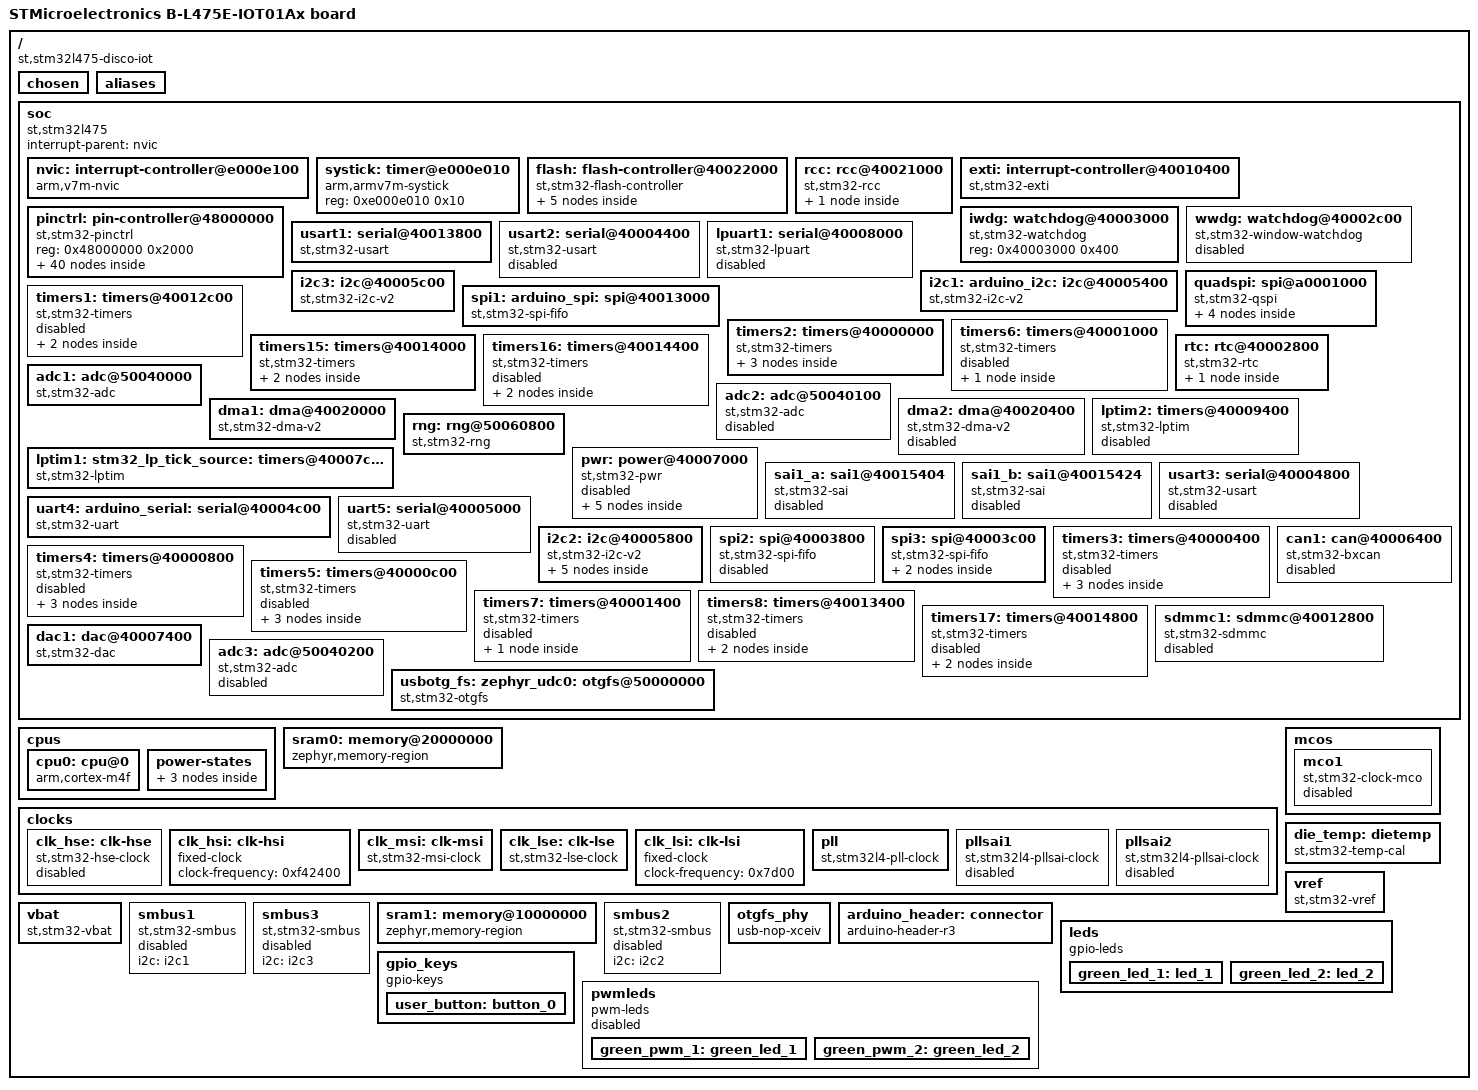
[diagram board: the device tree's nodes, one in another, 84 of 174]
/dts-v1/;

/* node '/' defined in zephyr/dts/common/skeleton.dtsi:9 */
/ {
	#address-cells = < 0x1 >;                           /* in zephyr/dts/common/skeleton.dtsi:10 */
	#size-cells = < 0x1 >;                              /* in zephyr/dts/common/skeleton.dtsi:11 */
	model = "STMicroelectronics B-L475E-IOT01Ax board"; /* in zephyr/boards/st/disco_l475_iot1/disco_l475_iot1.dts:14 */
	compatible = "st,stm32l475-disco-iot";              /* in zephyr/boards/st/disco_l475_iot1/disco_l475_iot1.dts:15 */

	/* node '/chosen' defined in zephyr/dts/common/skeleton.dtsi:13 */
	chosen {
		zephyr,entropy = &rng;                    /* in zephyr/dts/arm/st/l4/stm32l4.dtsi:26 */
		zephyr,console = &usart1;                 /* in zephyr/boards/st/disco_l475_iot1/disco_l475_iot1.dts:18 */
		zephyr,shell-uart = &usart1;              /* in zephyr/boards/st/disco_l475_iot1/disco_l475_iot1.dts:19 */
		zephyr,sram = &sram0;                     /* in zephyr/boards/st/disco_l475_iot1/disco_l475_iot1.dts:20 */
		zephyr,flash = &flash0;                   /* in zephyr/boards/st/disco_l475_iot1/disco_l475_iot1.dts:21 */
		zephyr,code-partition = &slot0_partition; /* in zephyr/boards/st/disco_l475_iot1/disco_l475_iot1.dts:22 */
		zephyr,flash-controller = &mx25r6435f;    /* in zephyr/boards/st/disco_l475_iot1/disco_l475_iot1.dts:23 */
		zephyr,bt-c2h-uart = &usart1;             /* in zephyr/boards/st/disco_l475_iot1/disco_l475_iot1.dts:24 */
		zephyr,bt-hci = &hci_spi;                 /* in zephyr/boards/st/disco_l475_iot1/disco_l475_iot1.dts:25 */
	};

	/* node '/aliases' defined in zephyr/dts/common/skeleton.dtsi:15 */
	aliases {
		led0 = &green_led_2;     /* in zephyr/boards/st/disco_l475_iot1/disco_l475_iot1.dts:73 */
		led1 = &green_led_1;     /* in zephyr/boards/st/disco_l475_iot1/disco_l475_iot1.dts:74 */
		pwm-led0 = &green_pwm_2; /* in zephyr/boards/st/disco_l475_iot1/disco_l475_iot1.dts:75 */
		pwm-led1 = &green_pwm_1; /* in zephyr/boards/st/disco_l475_iot1/disco_l475_iot1.dts:76 */
		sw0 = &user_button;      /* in zephyr/boards/st/disco_l475_iot1/disco_l475_iot1.dts:77 */
		eswifi0 = &wifi0;        /* in zephyr/boards/st/disco_l475_iot1/disco_l475_iot1.dts:78 */
		watchdog0 = &iwdg;       /* in zephyr/boards/st/disco_l475_iot1/disco_l475_iot1.dts:79 */
		accel0 = &lsm6dsl;       /* in zephyr/boards/st/disco_l475_iot1/disco_l475_iot1.dts:80 */
		volt-sensor0 = &vref;    /* in zephyr/boards/st/disco_l475_iot1/disco_l475_iot1.dts:81 */
		volt-sensor1 = &vbat;    /* in zephyr/boards/st/disco_l475_iot1/disco_l475_iot1.dts:82 */
		die-temp0 = &die_temp;   /* in zephyr/boards/st/disco_l475_iot1/disco_l475_iot1.dts:83 */
	};

	/* node '/soc' defined in zephyr/dts/arm/armv7-m.dtsi:6 */
	soc {
		#address-cells = < 0x1 >;     /* in zephyr/dts/arm/armv7-m.dtsi:7 */
		#size-cells = < 0x1 >;        /* in zephyr/dts/arm/armv7-m.dtsi:8 */
		interrupt-parent = < &nvic >; /* in zephyr/dts/arm/armv7-m.dtsi:10 */
		ranges;                       /* in zephyr/dts/arm/armv7-m.dtsi:11 */
		compatible = "st,stm32l475",
		             "st,stm32l4",
		             "simple-bus";    /* in zephyr/dts/arm/st/l4/stm32l475.dtsi:11 */

		/* node '/soc/interrupt-controller@e000e100' defined in zephyr/dts/arm/armv7-m.dtsi:13 */
		nvic: interrupt-controller@e000e100 {
			#address-cells = < 0x1 >;            /* in zephyr/dts/arm/armv7-m.dtsi:14 */
			compatible = "arm,v7m-nvic";         /* in zephyr/dts/arm/armv7-m.dtsi:15 */
			reg = < 0xe000e100 0xc00 >;          /* in zephyr/dts/arm/armv7-m.dtsi:16 */
			interrupt-controller;                /* in zephyr/dts/arm/armv7-m.dtsi:17 */
			#interrupt-cells = < 0x2 >;          /* in zephyr/dts/arm/armv7-m.dtsi:18 */
			arm,num-irq-priority-bits = < 0x4 >; /* in zephyr/dts/arm/st/l4/stm32l4.dtsi:596 */
			phandle = < 0x1 >;                   /* in zephyr/dts/arm/armv7-m.dtsi:10 */
		};

		/* node '/soc/timer@e000e010' defined in zephyr/dts/arm/armv7-m.dtsi:21 */
		systick: timer@e000e010 {
			compatible = "arm,armv7m-systick"; /* in zephyr/dts/arm/armv7-m.dtsi:22 */
			reg = < 0xe000e010 0x10 >;         /* in zephyr/dts/arm/armv7-m.dtsi:23 */
		};

		/* node '/soc/flash-controller@40022000' defined in zephyr/dts/arm/st/l4/stm32l4.dtsi:127 */
		flash: flash-controller@40022000 {
			compatible = "st,stm32-flash-controller",
			             "st,stm32l4-flash-controller"; /* in zephyr/dts/arm/st/l4/stm32l4.dtsi:128 */
			reg = < 0x40022000 0x400 >;                 /* in zephyr/dts/arm/st/l4/stm32l4.dtsi:129 */
			interrupts = < 0x4 0x0 >;                   /* in zephyr/dts/arm/st/l4/stm32l4.dtsi:130 */
			clocks = < &rcc 0x48 0x100 >;               /* in zephyr/dts/arm/st/l4/stm32l4.dtsi:131 */
			#address-cells = < 0x1 >;                   /* in zephyr/dts/arm/st/l4/stm32l4.dtsi:133 */
			#size-cells = < 0x1 >;                      /* in zephyr/dts/arm/st/l4/stm32l4.dtsi:134 */

			/* node '/soc/flash-controller@40022000/flash@8000000' defined in zephyr/dts/arm/st/l4/stm32l4.dtsi:136 */
			flash0: flash@8000000 {
				compatible = "st,stm32-nv-flash",
				             "soc-nv-flash";      /* in zephyr/dts/arm/st/l4/stm32l4.dtsi:137 */
				write-block-size = < 0x8 >;       /* in zephyr/dts/arm/st/l4/stm32l4.dtsi:139 */
				erase-block-size = < 0x800 >;     /* in zephyr/dts/arm/st/l4/stm32l4.dtsi:140 */
				max-erase-time = < 0x19 >;        /* in zephyr/dts/arm/st/l4/stm32l4.dtsi:142 */
				reg = < 0x8000000 0x100000 >;     /* in zephyr/dts/arm/st/l4/stm32l475Xg.dtsi:20 */

				/* node '/soc/flash-controller@40022000/flash@8000000/partitions' defined in zephyr/boards/st/disco_l475_iot1/disco_l475_iot1.dts:227 */
				partitions {
					compatible = "fixed-partitions"; /* in zephyr/boards/st/disco_l475_iot1/disco_l475_iot1.dts:228 */
					#address-cells = < 0x1 >;        /* in zephyr/boards/st/disco_l475_iot1/disco_l475_iot1.dts:229 */
					#size-cells = < 0x1 >;           /* in zephyr/boards/st/disco_l475_iot1/disco_l475_iot1.dts:230 */

					/* node '/soc/flash-controller@40022000/flash@8000000/partitions/partition@0' defined in zephyr/boards/st/disco_l475_iot1/disco_l475_iot1.dts:232 */
					boot_partition: partition@0 {
						label = "mcuboot";     /* in zephyr/boards/st/disco_l475_iot1/disco_l475_iot1.dts:233 */
						reg = < 0x0 0x10000 >; /* in zephyr/boards/st/disco_l475_iot1/disco_l475_iot1.dts:234 */
						read-only;             /* in zephyr/boards/st/disco_l475_iot1/disco_l475_iot1.dts:235 */
					};

					/* node '/soc/flash-controller@40022000/flash@8000000/partitions/partition@10000' defined in zephyr/boards/st/disco_l475_iot1/disco_l475_iot1.dts:238 */
					slot0_partition: partition@10000 {
						label = "image-0";         /* in zephyr/boards/st/disco_l475_iot1/disco_l475_iot1.dts:239 */
						reg = < 0x10000 0xe8000 >; /* in zephyr/boards/st/disco_l475_iot1/disco_l475_iot1.dts:240 */
					};

					/* node '/soc/flash-controller@40022000/flash@8000000/partitions/partition@f8000' defined in zephyr/boards/st/disco_l475_iot1/disco_l475_iot1.dts:243 */
					storage_partition: partition@f8000 {
						label = "storage";        /* in zephyr/boards/st/disco_l475_iot1/disco_l475_iot1.dts:244 */
						reg = < 0xf8000 0x8000 >; /* in zephyr/boards/st/disco_l475_iot1/disco_l475_iot1.dts:245 */
					};
				};
			};
		};

		/* node '/soc/rcc@40021000' defined in zephyr/dts/arm/st/l4/stm32l4.dtsi:146 */
		rcc: rcc@40021000 {
			compatible = "st,stm32-rcc";     /* in zephyr/dts/arm/st/l4/stm32l4.dtsi:147 */
			#clock-cells = < 0x2 >;          /* in zephyr/dts/arm/st/l4/stm32l4.dtsi:148 */
			reg = < 0x40021000 0x400 >;      /* in zephyr/dts/arm/st/l4/stm32l4.dtsi:149 */
			clocks = < &pll >;               /* in zephyr/boards/st/disco_l475_iot1/disco_l475_iot1.dts:116 */
			clock-frequency = < 0x4c4b400 >; /* in zephyr/boards/st/disco_l475_iot1/disco_l475_iot1.dts:117 */
			ahb-prescaler = < 0x1 >;         /* in zephyr/boards/st/disco_l475_iot1/disco_l475_iot1.dts:118 */
			apb1-prescaler = < 0x1 >;        /* in zephyr/boards/st/disco_l475_iot1/disco_l475_iot1.dts:119 */
			apb2-prescaler = < 0x1 >;        /* in zephyr/boards/st/disco_l475_iot1/disco_l475_iot1.dts:120 */
			phandle = < 0x2 >;               /* in zephyr/dts/arm/st/l4/stm32l4.dtsi:131 */

			/* node '/soc/rcc@40021000/reset-controller' defined in zephyr/dts/arm/st/l4/stm32l4.dtsi:151 */
			rctl: reset-controller {
				compatible = "st,stm32-rcc-rctl"; /* in zephyr/dts/arm/st/l4/stm32l4.dtsi:152 */
				#reset-cells = < 0x1 >;           /* in zephyr/dts/arm/st/l4/stm32l4.dtsi:153 */
				phandle = < 0x4 >;                /* in zephyr/dts/arm/st/l4/stm32l4.dtsi:230 */
			};
		};

		/* node '/soc/interrupt-controller@40010400' defined in zephyr/dts/arm/st/l4/stm32l4.dtsi:157 */
		exti: interrupt-controller@40010400 {
			compatible = "st,stm32-exti";  /* in zephyr/dts/arm/st/l4/stm32l4.dtsi:158 */
			interrupt-controller;          /* in zephyr/dts/arm/st/l4/stm32l4.dtsi:159 */
			#interrupt-cells = < 0x1 >;    /* in zephyr/dts/arm/st/l4/stm32l4.dtsi:160 */
			#address-cells = < 0x0 >;      /* in zephyr/dts/arm/st/l4/stm32l4.dtsi:161 */
			reg = < 0x40010400 0x400 >;    /* in zephyr/dts/arm/st/l4/stm32l4.dtsi:162 */
			clocks = < &rcc 0x60 0x1 >;    /* in zephyr/dts/arm/st/l4/stm32l4.dtsi:163 */
			num-lines = < 0x40 >;          /* in zephyr/dts/arm/st/l4/stm32l4.dtsi:164 */
			interrupts = < 0x6 0x0 >,
			             < 0x7 0x0 >,
			             < 0x8 0x0 >,
			             < 0x9 0x0 >,
			             < 0xa 0x0 >,
			             < 0x17 0x0 >,
			             < 0x28 0x0 >;     /* in zephyr/dts/arm/st/l4/stm32l4.dtsi:165 */
			interrupt-names = "line0",
			                  "line1",
			                  "line2",
			                  "line3",
			                  "line4",
			                  "line5-9",
			                  "line10-15"; /* in zephyr/dts/arm/st/l4/stm32l4.dtsi:167 */
			line-ranges = < 0x0 0x1 >,
			              < 0x1 0x1 >,
			              < 0x2 0x1 >,
			              < 0x3 0x1 >,
			              < 0x4 0x1 >,
			              < 0x5 0x5 >,
			              < 0xa 0x6 >;     /* in zephyr/dts/arm/st/l4/stm32l4.dtsi:169 */
		};

		/* node '/soc/pin-controller@48000000' defined in zephyr/dts/arm/st/l4/stm32l4.dtsi:173 */
		pinctrl: pin-controller@48000000 {
			compatible = "st,stm32-pinctrl"; /* in zephyr/dts/arm/st/l4/stm32l4.dtsi:174 */
			#address-cells = < 0x1 >;        /* in zephyr/dts/arm/st/l4/stm32l4.dtsi:175 */
			#size-cells = < 0x1 >;           /* in zephyr/dts/arm/st/l4/stm32l4.dtsi:176 */
			reg = < 0x48000000 0x2000 >;     /* in zephyr/dts/arm/st/l4/stm32l4.dtsi:177 */

			/* node '/soc/pin-controller@48000000/gpio@48000000' defined in zephyr/dts/arm/st/l4/stm32l4.dtsi:179 */
			gpioa: gpio@48000000 {
				compatible = "st,stm32-gpio"; /* in zephyr/dts/arm/st/l4/stm32l4.dtsi:180 */
				gpio-controller;              /* in zephyr/dts/arm/st/l4/stm32l4.dtsi:181 */
				#gpio-cells = < 0x2 >;        /* in zephyr/dts/arm/st/l4/stm32l4.dtsi:182 */
				reg = < 0x48000000 0x400 >;   /* in zephyr/dts/arm/st/l4/stm32l4.dtsi:183 */
				clocks = < &rcc 0x4c 0x1 >;   /* in zephyr/dts/arm/st/l4/stm32l4.dtsi:184 */
				phandle = < 0x15 >;           /* in zephyr/boards/st/disco_l475_iot1/disco_l475_iot1.dts:189 */
			};

			/* node '/soc/pin-controller@48000000/gpio@48000400' defined in zephyr/dts/arm/st/l4/stm32l4.dtsi:187 */
			gpiob: gpio@48000400 {
				compatible = "st,stm32-gpio"; /* in zephyr/dts/arm/st/l4/stm32l4.dtsi:188 */
				gpio-controller;              /* in zephyr/dts/arm/st/l4/stm32l4.dtsi:189 */
				#gpio-cells = < 0x2 >;        /* in zephyr/dts/arm/st/l4/stm32l4.dtsi:190 */
				reg = < 0x48000400 0x400 >;   /* in zephyr/dts/arm/st/l4/stm32l4.dtsi:191 */
				clocks = < &rcc 0x4c 0x2 >;   /* in zephyr/dts/arm/st/l4/stm32l4.dtsi:192 */
				phandle = < 0x27 >;           /* in zephyr/boards/st/disco_l475_iot1/disco_l475_iot1.dts:220 */
			};

			/* node '/soc/pin-controller@48000000/gpio@48000800' defined in zephyr/dts/arm/st/l4/stm32l4.dtsi:195 */
			gpioc: gpio@48000800 {
				compatible = "st,stm32-gpio"; /* in zephyr/dts/arm/st/l4/stm32l4.dtsi:196 */
				gpio-controller;              /* in zephyr/dts/arm/st/l4/stm32l4.dtsi:197 */
				#gpio-cells = < 0x2 >;        /* in zephyr/dts/arm/st/l4/stm32l4.dtsi:198 */
				reg = < 0x48000800 0x400 >;   /* in zephyr/dts/arm/st/l4/stm32l4.dtsi:199 */
				clocks = < &rcc 0x4c 0x4 >;   /* in zephyr/dts/arm/st/l4/stm32l4.dtsi:200 */
				phandle = < 0x22 >;           /* in zephyr/boards/st/disco_l475_iot1/disco_l475_iot1.dts:175 */
			};

			/* node '/soc/pin-controller@48000000/gpio@48001c00' defined in zephyr/dts/arm/st/l4/stm32l4.dtsi:203 */
			gpioh: gpio@48001c00 {
				compatible = "st,stm32-gpio"; /* in zephyr/dts/arm/st/l4/stm32l4.dtsi:204 */
				gpio-controller;              /* in zephyr/dts/arm/st/l4/stm32l4.dtsi:205 */
				#gpio-cells = < 0x2 >;        /* in zephyr/dts/arm/st/l4/stm32l4.dtsi:206 */
				reg = < 0x48001c00 0x400 >;   /* in zephyr/dts/arm/st/l4/stm32l4.dtsi:207 */
				clocks = < &rcc 0x4c 0x80 >;  /* in zephyr/dts/arm/st/l4/stm32l4.dtsi:208 */
			};

			/* node '/soc/pin-controller@48000000/gpio@48000c00' defined in zephyr/dts/arm/st/l4/stm32l471.dtsi:29 */
			gpiod: gpio@48000c00 {
				compatible = "st,stm32-gpio"; /* in zephyr/dts/arm/st/l4/stm32l471.dtsi:30 */
				gpio-controller;              /* in zephyr/dts/arm/st/l4/stm32l471.dtsi:31 */
				#gpio-cells = < 0x2 >;        /* in zephyr/dts/arm/st/l4/stm32l471.dtsi:32 */
				reg = < 0x48000c00 0x400 >;   /* in zephyr/dts/arm/st/l4/stm32l471.dtsi:33 */
				clocks = < &rcc 0x4c 0x8 >;   /* in zephyr/dts/arm/st/l4/stm32l471.dtsi:34 */
				phandle = < 0x21 >;           /* in zephyr/boards/st/disco_l475_iot1/disco_l475_iot1.dts:158 */
			};

			/* node '/soc/pin-controller@48000000/gpio@48001000' defined in zephyr/dts/arm/st/l4/stm32l471.dtsi:37 */
			gpioe: gpio@48001000 {
				compatible = "st,stm32-gpio"; /* in zephyr/dts/arm/st/l4/stm32l471.dtsi:38 */
				gpio-controller;              /* in zephyr/dts/arm/st/l4/stm32l471.dtsi:39 */
				#gpio-cells = < 0x2 >;        /* in zephyr/dts/arm/st/l4/stm32l471.dtsi:40 */
				reg = < 0x48001000 0x400 >;   /* in zephyr/dts/arm/st/l4/stm32l471.dtsi:41 */
				clocks = < &rcc 0x4c 0x10 >;  /* in zephyr/dts/arm/st/l4/stm32l471.dtsi:42 */
				phandle = < 0x26 >;           /* in zephyr/boards/st/disco_l475_iot1/disco_l475_iot1.dts:203 */
			};

			/* node '/soc/pin-controller@48000000/gpio@48001400' defined in zephyr/dts/arm/st/l4/stm32l471.dtsi:45 */
			gpiof: gpio@48001400 {
				compatible = "st,stm32-gpio"; /* in zephyr/dts/arm/st/l4/stm32l471.dtsi:46 */
				gpio-controller;              /* in zephyr/dts/arm/st/l4/stm32l471.dtsi:47 */
				#gpio-cells = < 0x2 >;        /* in zephyr/dts/arm/st/l4/stm32l471.dtsi:48 */
				reg = < 0x48001400 0x400 >;   /* in zephyr/dts/arm/st/l4/stm32l471.dtsi:49 */
				clocks = < &rcc 0x4c 0x20 >;  /* in zephyr/dts/arm/st/l4/stm32l471.dtsi:50 */
			};

			/* node '/soc/pin-controller@48000000/gpio@48001800' defined in zephyr/dts/arm/st/l4/stm32l471.dtsi:53 */
			gpiog: gpio@48001800 {
				compatible = "st,stm32-gpio"; /* in zephyr/dts/arm/st/l4/stm32l471.dtsi:54 */
				gpio-controller;              /* in zephyr/dts/arm/st/l4/stm32l471.dtsi:55 */
				#gpio-cells = < 0x2 >;        /* in zephyr/dts/arm/st/l4/stm32l471.dtsi:56 */
				reg = < 0x48001800 0x400 >;   /* in zephyr/dts/arm/st/l4/stm32l471.dtsi:57 */
				clocks = < &rcc 0x4c 0x40 >;  /* in zephyr/dts/arm/st/l4/stm32l471.dtsi:58 */
			};

			/* node '/soc/pin-controller@48000000/adc1_in3_pc2' defined in modules/hal/stm32/dts/st/l4/stm32l475v(c-e-g)tx-pinctrl.dtsi:63 */
			adc1_in3_pc2: adc1_in3_pc2 {
				pinmux = < 0x450 >; /* in modules/hal/stm32/dts/st/l4/stm32l475v(c-e-g)tx-pinctrl.dtsi:64 */
				phandle = < 0x18 >; /* in zephyr/boards/st/disco_l475_iot1/disco_l475_iot1.dts:300 */
			};

			/* node '/soc/pin-controller@48000000/adc1_in4_pc3' defined in modules/hal/stm32/dts/st/l4/stm32l475v(c-e-g)tx-pinctrl.dtsi:67 */
			adc1_in4_pc3: adc1_in4_pc3 {
				pinmux = < 0x470 >; /* in modules/hal/stm32/dts/st/l4/stm32l475v(c-e-g)tx-pinctrl.dtsi:68 */
				phandle = < 0x19 >; /* in zephyr/boards/st/disco_l475_iot1/disco_l475_iot1.dts:300 */
			};

			/* node '/soc/pin-controller@48000000/adc1_in13_pc4' defined in modules/hal/stm32/dts/st/l4/stm32l475v(c-e-g)tx-pinctrl.dtsi:71 */
			adc1_in13_pc4: adc1_in13_pc4 {
				pinmux = < 0x490 >; /* in modules/hal/stm32/dts/st/l4/stm32l475v(c-e-g)tx-pinctrl.dtsi:72 */
				phandle = < 0x1a >; /* in zephyr/boards/st/disco_l475_iot1/disco_l475_iot1.dts:300 */
			};

			/* node '/soc/pin-controller@48000000/adc1_in14_pc5' defined in modules/hal/stm32/dts/st/l4/stm32l475v(c-e-g)tx-pinctrl.dtsi:75 */
			adc1_in14_pc5: adc1_in14_pc5 {
				pinmux = < 0x4b0 >; /* in modules/hal/stm32/dts/st/l4/stm32l475v(c-e-g)tx-pinctrl.dtsi:76 */
				phandle = < 0x1b >; /* in zephyr/boards/st/disco_l475_iot1/disco_l475_iot1.dts:300 */
			};

			/* node '/soc/pin-controller@48000000/dac1_out1_pa4' defined in modules/hal/stm32/dts/st/l4/stm32l475v(c-e-g)tx-pinctrl.dtsi:574 */
			dac1_out1_pa4: dac1_out1_pa4 {
				pinmux = < 0x90 >;  /* in modules/hal/stm32/dts/st/l4/stm32l475v(c-e-g)tx-pinctrl.dtsi:575 */
				phandle = < 0x28 >; /* in zephyr/boards/st/disco_l475_iot1/disco_l475_iot1.dts:314 */
			};

			/* node '/soc/pin-controller@48000000/i2c1_scl_pb8' defined in modules/hal/stm32/dts/st/l4/stm32l475v(c-e-g)tx-pinctrl.dtsi:958 */
			i2c1_scl_pb8: i2c1_scl_pb8 {
				pinmux = < 0x304 >; /* in modules/hal/stm32/dts/st/l4/stm32l475v(c-e-g)tx-pinctrl.dtsi:959 */
				bias-pull-up;       /* in modules/hal/stm32/dts/st/l4/stm32l475v(c-e-g)tx-pinctrl.dtsi:960 */
				drive-open-drain;   /* in modules/hal/stm32/dts/st/l4/stm32l475v(c-e-g)tx-pinctrl.dtsi:961 */
				phandle = < 0x7 >;  /* in zephyr/boards/st/disco_l475_iot1/disco_l475_iot1.dts:138 */
			};

			/* node '/soc/pin-controller@48000000/i2c2_scl_pb10' defined in modules/hal/stm32/dts/st/l4/stm32l475v(c-e-g)tx-pinctrl.dtsi:964 */
			i2c2_scl_pb10: i2c2_scl_pb10 {
				pinmux = < 0x344 >; /* in modules/hal/stm32/dts/st/l4/stm32l475v(c-e-g)tx-pinctrl.dtsi:965 */
				bias-pull-up;       /* in modules/hal/stm32/dts/st/l4/stm32l475v(c-e-g)tx-pinctrl.dtsi:966 */
				drive-open-drain;   /* in modules/hal/stm32/dts/st/l4/stm32l475v(c-e-g)tx-pinctrl.dtsi:967 */
				phandle = < 0x1f >; /* in zephyr/boards/st/disco_l475_iot1/disco_l475_iot1.dts:145 */
			};

			/* node '/soc/pin-controller@48000000/i2c3_scl_pc0' defined in modules/hal/stm32/dts/st/l4/stm32l475v(c-e-g)tx-pinctrl.dtsi:976 */
			i2c3_scl_pc0: i2c3_scl_pc0 {
				pinmux = < 0x404 >; /* in modules/hal/stm32/dts/st/l4/stm32l475v(c-e-g)tx-pinctrl.dtsi:977 */
				bias-pull-up;       /* in modules/hal/stm32/dts/st/l4/stm32l475v(c-e-g)tx-pinctrl.dtsi:978 */
				drive-open-drain;   /* in modules/hal/stm32/dts/st/l4/stm32l475v(c-e-g)tx-pinctrl.dtsi:979 */
				phandle = < 0x9 >;  /* in zephyr/boards/st/disco_l475_iot1/disco_l475_iot1.dts:180 */
			};

			/* node '/soc/pin-controller@48000000/i2c1_sda_pb9' defined in modules/hal/stm32/dts/st/l4/stm32l475v(c-e-g)tx-pinctrl.dtsi:990 */
			i2c1_sda_pb9: i2c1_sda_pb9 {
				pinmux = < 0x324 >; /* in modules/hal/stm32/dts/st/l4/stm32l475v(c-e-g)tx-pinctrl.dtsi:991 */
				bias-pull-up;       /* in modules/hal/stm32/dts/st/l4/stm32l475v(c-e-g)tx-pinctrl.dtsi:992 */
				drive-open-drain;   /* in modules/hal/stm32/dts/st/l4/stm32l475v(c-e-g)tx-pinctrl.dtsi:993 */
				phandle = < 0x8 >;  /* in zephyr/boards/st/disco_l475_iot1/disco_l475_iot1.dts:138 */
			};

			/* node '/soc/pin-controller@48000000/i2c2_sda_pb11' defined in modules/hal/stm32/dts/st/l4/stm32l475v(c-e-g)tx-pinctrl.dtsi:996 */
			i2c2_sda_pb11: i2c2_sda_pb11 {
				pinmux = < 0x364 >; /* in modules/hal/stm32/dts/st/l4/stm32l475v(c-e-g)tx-pinctrl.dtsi:997 */
				bias-pull-up;       /* in modules/hal/stm32/dts/st/l4/stm32l475v(c-e-g)tx-pinctrl.dtsi:998 */
				drive-open-drain;   /* in modules/hal/stm32/dts/st/l4/stm32l475v(c-e-g)tx-pinctrl.dtsi:999 */
				phandle = < 0x20 >; /* in zephyr/boards/st/disco_l475_iot1/disco_l475_iot1.dts:145 */
			};

			/* node '/soc/pin-controller@48000000/i2c3_sda_pc1' defined in modules/hal/stm32/dts/st/l4/stm32l475v(c-e-g)tx-pinctrl.dtsi:1008 */
			i2c3_sda_pc1: i2c3_sda_pc1 {
				pinmux = < 0x424 >; /* in modules/hal/stm32/dts/st/l4/stm32l475v(c-e-g)tx-pinctrl.dtsi:1009 */
				bias-pull-up;       /* in modules/hal/stm32/dts/st/l4/stm32l475v(c-e-g)tx-pinctrl.dtsi:1010 */
				drive-open-drain;   /* in modules/hal/stm32/dts/st/l4/stm32l475v(c-e-g)tx-pinctrl.dtsi:1011 */
				phandle = < 0xa >;  /* in zephyr/boards/st/disco_l475_iot1/disco_l475_iot1.dts:180 */
			};

			/* node '/soc/pin-controller@48000000/quadspi_clk_pe10' defined in modules/hal/stm32/dts/st/l4/stm32l475v(c-e-g)tx-pinctrl.dtsi:1111 */
			quadspi_clk_pe10: quadspi_clk_pe10 {
				pinmux = < 0x94a >;            /* in modules/hal/stm32/dts/st/l4/stm32l475v(c-e-g)tx-pinctrl.dtsi:1112 */
				slew-rate = "very-high-speed"; /* in modules/hal/stm32/dts/st/l4/stm32l475v(c-e-g)tx-pinctrl.dtsi:1113 */
				phandle = < 0xb >;             /* in zephyr/boards/st/disco_l475_iot1/disco_l475_iot1.dts:323 */
			};

			/* node '/soc/pin-controller@48000000/quadspi_ncs_pe11' defined in modules/hal/stm32/dts/st/l4/stm32l475v(c-e-g)tx-pinctrl.dtsi:1116 */
			quadspi_ncs_pe11: quadspi_ncs_pe11 {
				pinmux = < 0x96a >;            /* in modules/hal/stm32/dts/st/l4/stm32l475v(c-e-g)tx-pinctrl.dtsi:1117 */
				slew-rate = "very-high-speed"; /* in modules/hal/stm32/dts/st/l4/stm32l475v(c-e-g)tx-pinctrl.dtsi:1118 */
				phandle = < 0xc >;             /* in zephyr/boards/st/disco_l475_iot1/disco_l475_iot1.dts:323 */
			};

			/* node '/soc/pin-controller@48000000/quadspi_bk1_io0_pe12' defined in modules/hal/stm32/dts/st/l4/stm32l475v(c-e-g)tx-pinctrl.dtsi:1121 */
			quadspi_bk1_io0_pe12: quadspi_bk1_io0_pe12 {
				pinmux = < 0x98a >;            /* in modules/hal/stm32/dts/st/l4/stm32l475v(c-e-g)tx-pinctrl.dtsi:1122 */
				slew-rate = "very-high-speed"; /* in modules/hal/stm32/dts/st/l4/stm32l475v(c-e-g)tx-pinctrl.dtsi:1123 */
				phandle = < 0xd >;             /* in zephyr/boards/st/disco_l475_iot1/disco_l475_iot1.dts:323 */
			};

			/* node '/soc/pin-controller@48000000/quadspi_bk1_io1_pe13' defined in modules/hal/stm32/dts/st/l4/stm32l475v(c-e-g)tx-pinctrl.dtsi:1126 */
			quadspi_bk1_io1_pe13: quadspi_bk1_io1_pe13 {
				pinmux = < 0x9aa >;            /* in modules/hal/stm32/dts/st/l4/stm32l475v(c-e-g)tx-pinctrl.dtsi:1127 */
				slew-rate = "very-high-speed"; /* in modules/hal/stm32/dts/st/l4/stm32l475v(c-e-g)tx-pinctrl.dtsi:1128 */
				phandle = < 0xe >;             /* in zephyr/boards/st/disco_l475_iot1/disco_l475_iot1.dts:323 */
			};

			/* node '/soc/pin-controller@48000000/quadspi_bk1_io2_pe14' defined in modules/hal/stm32/dts/st/l4/stm32l475v(c-e-g)tx-pinctrl.dtsi:1131 */
			quadspi_bk1_io2_pe14: quadspi_bk1_io2_pe14 {
				pinmux = < 0x9ca >;            /* in modules/hal/stm32/dts/st/l4/stm32l475v(c-e-g)tx-pinctrl.dtsi:1132 */
				slew-rate = "very-high-speed"; /* in modules/hal/stm32/dts/st/l4/stm32l475v(c-e-g)tx-pinctrl.dtsi:1133 */
				phandle = < 0xf >;             /* in zephyr/boards/st/disco_l475_iot1/disco_l475_iot1.dts:323 */
			};

			/* node '/soc/pin-controller@48000000/quadspi_bk1_io3_pe15' defined in modules/hal/stm32/dts/st/l4/stm32l475v(c-e-g)tx-pinctrl.dtsi:1136 */
			quadspi_bk1_io3_pe15: quadspi_bk1_io3_pe15 {
				pinmux = < 0x9ea >;            /* in modules/hal/stm32/dts/st/l4/stm32l475v(c-e-g)tx-pinctrl.dtsi:1137 */
				slew-rate = "very-high-speed"; /* in modules/hal/stm32/dts/st/l4/stm32l475v(c-e-g)tx-pinctrl.dtsi:1138 */
				phandle = < 0x10 >;            /* in zephyr/boards/st/disco_l475_iot1/disco_l475_iot1.dts:323 */
			};

			/* node '/soc/pin-controller@48000000/spi1_miso_pa6' defined in modules/hal/stm32/dts/st/l4/stm32l475v(c-e-g)tx-pinctrl.dtsi:1358 */
			spi1_miso_pa6: spi1_miso_pa6 {
				pinmux = < 0xc5 >;  /* in modules/hal/stm32/dts/st/l4/stm32l475v(c-e-g)tx-pinctrl.dtsi:1359 */
				bias-pull-down;     /* in modules/hal/stm32/dts/st/l4/stm32l475v(c-e-g)tx-pinctrl.dtsi:1360 */
				phandle = < 0x13 >; /* in zephyr/boards/st/disco_l475_iot1/disco_l475_iot1.dts:187 */
			};

			/* node '/soc/pin-controller@48000000/spi3_miso_pc11' defined in modules/hal/stm32/dts/st/l4/stm32l475v(c-e-g)tx-pinctrl.dtsi:1393 */
			spi3_miso_pc11: spi3_miso_pc11 {
				pinmux = < 0x566 >;            /* in modules/hal/stm32/dts/st/l4/stm32l475v(c-e-g)tx-pinctrl.dtsi:1394 */
				bias-pull-down;                /* in modules/hal/stm32/dts/st/l4/stm32l475v(c-e-g)tx-pinctrl.dtsi:1395 */
				slew-rate = "very-high-speed"; /* in zephyr/boards/st/disco_l475_iot1/disco_l475_iot1.dts:194 */
				phandle = < 0x24 >;            /* in zephyr/boards/st/disco_l475_iot1/disco_l475_iot1.dts:200 */
			};

			/* node '/soc/pin-controller@48000000/spi1_mosi_pa7' defined in modules/hal/stm32/dts/st/l4/stm32l475v(c-e-g)tx-pinctrl.dtsi:1400 */
			spi1_mosi_pa7: spi1_mosi_pa7 {
				pinmux = < 0xe5 >;  /* in modules/hal/stm32/dts/st/l4/stm32l475v(c-e-g)tx-pinctrl.dtsi:1401 */
				bias-pull-down;     /* in modules/hal/stm32/dts/st/l4/stm32l475v(c-e-g)tx-pinctrl.dtsi:1402 */
				phandle = < 0x14 >; /* in zephyr/boards/st/disco_l475_iot1/disco_l475_iot1.dts:187 */
			};

			/* node '/soc/pin-controller@48000000/spi3_mosi_pc12' defined in modules/hal/stm32/dts/st/l4/stm32l475v(c-e-g)tx-pinctrl.dtsi:1435 */
			spi3_mosi_pc12: spi3_mosi_pc12 {
				pinmux = < 0x586 >; /* in modules/hal/stm32/dts/st/l4/stm32l475v(c-e-g)tx-pinctrl.dtsi:1436 */
				bias-pull-down;     /* in modules/hal/stm32/dts/st/l4/stm32l475v(c-e-g)tx-pinctrl.dtsi:1437 */
				phandle = < 0x25 >; /* in zephyr/boards/st/disco_l475_iot1/disco_l475_iot1.dts:200 */
			};

			/* node '/soc/pin-controller@48000000/spi1_sck_pa5' defined in modules/hal/stm32/dts/st/l4/stm32l475v(c-e-g)tx-pinctrl.dtsi:1484 */
			spi1_sck_pa5: spi1_sck_pa5 {
				pinmux = < 0xa5 >;             /* in modules/hal/stm32/dts/st/l4/stm32l475v(c-e-g)tx-pinctrl.dtsi:1485 */
				bias-pull-down;                /* in modules/hal/stm32/dts/st/l4/stm32l475v(c-e-g)tx-pinctrl.dtsi:1486 */
				slew-rate = "very-high-speed"; /* in modules/hal/stm32/dts/st/l4/stm32l475v(c-e-g)tx-pinctrl.dtsi:1487 */
				phandle = < 0x12 >;            /* in zephyr/boards/st/disco_l475_iot1/disco_l475_iot1.dts:187 */
			};

			/* node '/soc/pin-controller@48000000/spi3_sck_pc10' defined in modules/hal/stm32/dts/st/l4/stm32l475v(c-e-g)tx-pinctrl.dtsi:1526 */
			spi3_sck_pc10: spi3_sck_pc10 {
				pinmux = < 0x546 >;            /* in modules/hal/stm32/dts/st/l4/stm32l475v(c-e-g)tx-pinctrl.dtsi:1527 */
				bias-pull-down;                /* in modules/hal/stm32/dts/st/l4/stm32l475v(c-e-g)tx-pinctrl.dtsi:1528 */
				slew-rate = "very-high-speed"; /* in modules/hal/stm32/dts/st/l4/stm32l475v(c-e-g)tx-pinctrl.dtsi:1529 */
				phandle = < 0x23 >;            /* in zephyr/boards/st/disco_l475_iot1/disco_l475_iot1.dts:200 */
			};

			/* node '/soc/pin-controller@48000000/tim2_ch1_pa15' defined in modules/hal/stm32/dts/st/l4/stm32l475v(c-e-g)tx-pinctrl.dtsi:1680 */
			tim2_ch1_pa15: tim2_ch1_pa15 {
				pinmux = < 0x1e1 >; /* in modules/hal/stm32/dts/st/l4/stm32l475v(c-e-g)tx-pinctrl.dtsi:1681 */
				phandle = < 0x16 >; /* in zephyr/boards/st/disco_l475_iot1/disco_l475_iot1.dts:256 */
			};

			/* node '/soc/pin-controller@48000000/tim15_ch1_pb14' defined in modules/hal/stm32/dts/st/l4/stm32l475v(c-e-g)tx-pinctrl.dtsi:1816 */
			tim15_ch1_pb14: tim15_ch1_pb14 {
				pinmux = < 0x3ce >; /* in modules/hal/stm32/dts/st/l4/stm32l475v(c-e-g)tx-pinctrl.dtsi:1817 */
				phandle = < 0x17 >; /* in zephyr/boards/st/disco_l475_iot1/disco_l475_iot1.dts:267 */
			};

			/* node '/soc/pin-controller@48000000/usart1_rx_pb7' defined in modules/hal/stm32/dts/st/l4/stm32l475v(c-e-g)tx-pinctrl.dtsi:2186 */
			usart1_rx_pb7: usart1_rx_pb7 {
				pinmux = < 0x2e7 >; /* in modules/hal/stm32/dts/st/l4/stm32l475v(c-e-g)tx-pinctrl.dtsi:2187 */
				phandle = < 0x6 >;  /* in zephyr/boards/st/disco_l475_iot1/disco_l475_iot1.dts:125 */
			};

			/* node '/soc/pin-controller@48000000/uart4_rx_pa1' defined in modules/hal/stm32/dts/st/l4/stm32l475v(c-e-g)tx-pinctrl.dtsi:2222 */
			uart4_rx_pa1: uart4_rx_pa1 {
				pinmux = < 0x28 >;  /* in modules/hal/stm32/dts/st/l4/stm32l475v(c-e-g)tx-pinctrl.dtsi:2223 */
				phandle = < 0x1e >; /* in zephyr/boards/st/disco_l475_iot1/disco_l475_iot1.dts:131 */
			};

			/* node '/soc/pin-controller@48000000/usart1_tx_pb6' defined in modules/hal/stm32/dts/st/l4/stm32l475v(c-e-g)tx-pinctrl.dtsi:2241 */
			usart1_tx_pb6: usart1_tx_pb6 {
				pinmux = < 0x2c7 >; /* in modules/hal/stm32/dts/st/l4/stm32l475v(c-e-g)tx-pinctrl.dtsi:2242 */
				bias-pull-up;       /* in modules/hal/stm32/dts/st/l4/stm32l475v(c-e-g)tx-pinctrl.dtsi:2243 */
				phandle = < 0x5 >;  /* in zephyr/boards/st/disco_l475_iot1/disco_l475_iot1.dts:125 */
			};

			/* node '/soc/pin-controller@48000000/uart4_tx_pa0' defined in modules/hal/stm32/dts/st/l4/stm32l475v(c-e-g)tx-pinctrl.dtsi:2286 */
			uart4_tx_pa0: uart4_tx_pa0 {
				pinmux = < 0x8 >;   /* in modules/hal/stm32/dts/st/l4/stm32l475v(c-e-g)tx-pinctrl.dtsi:2287 */
				bias-pull-up;       /* in modules/hal/stm32/dts/st/l4/stm32l475v(c-e-g)tx-pinctrl.dtsi:2288 */
				phandle = < 0x1d >; /* in zephyr/boards/st/disco_l475_iot1/disco_l475_iot1.dts:131 */
			};

			/* node '/soc/pin-controller@48000000/usb_otg_fs_id_pa10' defined in modules/hal/stm32/dts/st/l4/stm32l475v(c-e-g)tx-pinctrl.dtsi:2311 */
			usb_otg_fs_id_pa10: usb_otg_fs_id_pa10 {
				pinmux = < 0x14a >; /* in modules/hal/stm32/dts/st/l4/stm32l475v(c-e-g)tx-pinctrl.dtsi:2312 */
				phandle = < 0x2c >; /* in zephyr/boards/st/disco_l475_iot1/disco_l475_iot1.dts:285 */
			};

			/* node '/soc/pin-controller@48000000/usb_otg_fs_dm_pa11' defined in modules/hal/stm32/dts/st/l4/stm32l475v(c-e-g)tx-pinctrl.dtsi:2315 */
			usb_otg_fs_dm_pa11: usb_otg_fs_dm_pa11 {
				pinmux = < 0x16a >; /* in modules/hal/stm32/dts/st/l4/stm32l475v(c-e-g)tx-pinctrl.dtsi:2316 */
				phandle = < 0x2a >; /* in zephyr/boards/st/disco_l475_iot1/disco_l475_iot1.dts:285 */
			};

			/* node '/soc/pin-controller@48000000/usb_otg_fs_dp_pa12' defined in modules/hal/stm32/dts/st/l4/stm32l475v(c-e-g)tx-pinctrl.dtsi:2319 */
			usb_otg_fs_dp_pa12: usb_otg_fs_dp_pa12 {
				pinmux = < 0x18a >; /* in modules/hal/stm32/dts/st/l4/stm32l475v(c-e-g)tx-pinctrl.dtsi:2320 */
				phandle = < 0x2b >; /* in zephyr/boards/st/disco_l475_iot1/disco_l475_iot1.dts:285 */
			};
		};

		/* node '/soc/watchdog@40003000' defined in zephyr/dts/arm/st/l4/stm32l4.dtsi:212 */
		iwdg: watchdog@40003000 {
			compatible = "st,stm32-watchdog"; /* in zephyr/dts/arm/st/l4/stm32l4.dtsi:213 */
			reg = < 0x40003000 0x400 >;       /* in zephyr/dts/arm/st/l4/stm32l4.dtsi:214 */
			status = "okay";                  /* in zephyr/boards/st/disco_l475_iot1/disco_l475_iot1.dts:292 */
		};

		/* node '/soc/watchdog@40002c00' defined in zephyr/dts/arm/st/l4/stm32l4.dtsi:218 */
		wwdg: watchdog@40002c00 {
			compatible = "st,stm32-window-watchdog"; /* in zephyr/dts/arm/st/l4/stm32l4.dtsi:219 */
			reg = < 0x40002c00 0x400 >;              /* in zephyr/dts/arm/st/l4/stm32l4.dtsi:220 */
			clocks = < &rcc 0x58 0x800 >;            /* in zephyr/dts/arm/st/l4/stm32l4.dtsi:221 */
			interrupts = < 0x0 0x7 >;                /* in zephyr/dts/arm/st/l4/stm32l4.dtsi:222 */
			status = "disabled";                     /* in zephyr/dts/arm/st/l4/stm32l4.dtsi:223 */
		};

		/* node '/soc/serial@40013800' defined in zephyr/dts/arm/st/l4/stm32l4.dtsi:226 */
		usart1: serial@40013800 {
			compatible = "st,stm32-usart",
			             "st,stm32-uart";                  /* in zephyr/dts/arm/st/l4/stm32l4.dtsi:227 */
			reg = < 0x40013800 0x400 >;                    /* in zephyr/dts/arm/st/l4/stm32l4.dtsi:228 */
			clocks = < &rcc 0x60 0x4000 >;                 /* in zephyr/dts/arm/st/l4/stm32l4.dtsi:229 */
			resets = < &rctl 0x80e >;                      /* in zephyr/dts/arm/st/l4/stm32l4.dtsi:230 */
			interrupts = < 0x25 0x0 >;                     /* in zephyr/dts/arm/st/l4/stm32l4.dtsi:231 */
			current-speed = < 0x1c200 >;                   /* in zephyr/boards/st/disco_l475_iot1/disco_l475_iot1.dts:124 */
			pinctrl-0 = < &usart1_tx_pb6 &usart1_rx_pb7 >; /* in zephyr/boards/st/disco_l475_iot1/disco_l475_iot1.dts:125 */
			pinctrl-names = "default";                     /* in zephyr/boards/st/disco_l475_iot1/disco_l475_iot1.dts:126 */
			status = "okay";                               /* in zephyr/boards/st/disco_l475_iot1/disco_l475_iot1.dts:127 */
		};

		/* node '/soc/serial@40004400' defined in zephyr/dts/arm/st/l4/stm32l4.dtsi:235 */
		usart2: serial@40004400 {
			compatible = "st,stm32-usart",
			             "st,stm32-uart";   /* in zephyr/dts/arm/st/l4/stm32l4.dtsi:236 */
			reg = < 0x40004400 0x400 >;     /* in zephyr/dts/arm/st/l4/stm32l4.dtsi:237 */
			clocks = < &rcc 0x58 0x20000 >; /* in zephyr/dts/arm/st/l4/stm32l4.dtsi:238 */
			resets = < &rctl 0x711 >;       /* in zephyr/dts/arm/st/l4/stm32l4.dtsi:239 */
			interrupts = < 0x26 0x0 >;      /* in zephyr/dts/arm/st/l4/stm32l4.dtsi:240 */
			status = "disabled";            /* in zephyr/dts/arm/st/l4/stm32l4.dtsi:241 */
		};

		/* node '/soc/serial@40008000' defined in zephyr/dts/arm/st/l4/stm32l4.dtsi:244 */
		lpuart1: serial@40008000 {
			compatible = "st,stm32-lpuart",
			             "st,stm32-uart";   /* in zephyr/dts/arm/st/l4/stm32l4.dtsi:245 */
			reg = < 0x40008000 0x400 >;     /* in zephyr/dts/arm/st/l4/stm32l4.dtsi:246 */
			clocks = < &rcc 0x5c 0x1 >;     /* in zephyr/dts/arm/st/l4/stm32l4.dtsi:247 */
			resets = < &rctl 0x780 >;       /* in zephyr/dts/arm/st/l4/stm32l4.dtsi:248 */
			interrupts = < 0x46 0x0 >;      /* in zephyr/dts/arm/st/l4/stm32l4.dtsi:249 */
			status = "disabled";            /* in zephyr/dts/arm/st/l4/stm32l4.dtsi:250 */
		};

		/* node '/soc/i2c@40005400' defined in zephyr/dts/arm/st/l4/stm32l4.dtsi:253 */
		i2c1: arduino_i2c: i2c@40005400 {
			compatible = "st,stm32-i2c-v2";              /* in zephyr/dts/arm/st/l4/stm32l4.dtsi:254 */
			#address-cells = < 0x1 >;                    /* in zephyr/dts/arm/st/l4/stm32l4.dtsi:256 */
			#size-cells = < 0x0 >;                       /* in zephyr/dts/arm/st/l4/stm32l4.dtsi:257 */
			reg = < 0x40005400 0x400 >;                  /* in zephyr/dts/arm/st/l4/stm32l4.dtsi:258 */
			clocks = < &rcc 0x58 0x200000 >;             /* in zephyr/dts/arm/st/l4/stm32l4.dtsi:259 */
			interrupts = < 0x1f 0x0 >,
			             < 0x20 0x0 >;                   /* in zephyr/dts/arm/st/l4/stm32l4.dtsi:260 */
			interrupt-names = "event",
			                  "error";                   /* in zephyr/dts/arm/st/l4/stm32l4.dtsi:261 */
			pinctrl-0 = < &i2c1_scl_pb8 &i2c1_sda_pb9 >; /* in zephyr/boards/st/disco_l475_iot1/disco_l475_iot1.dts:138 */
			pinctrl-names = "default";                   /* in zephyr/boards/st/disco_l475_iot1/disco_l475_iot1.dts:139 */
			status = "okay";                             /* in zephyr/boards/st/disco_l475_iot1/disco_l475_iot1.dts:140 */
			clock-frequency = < 0x61a80 >;               /* in zephyr/boards/st/disco_l475_iot1/disco_l475_iot1.dts:141 */
			phandle = < 0x32 >;                          /* in zephyr/dts/arm/st/l4/stm32l4.dtsi:582 */
		};

		/* node '/soc/i2c@40005c00' defined in zephyr/dts/arm/st/l4/stm32l4.dtsi:265 */
		i2c3: i2c@40005c00 {
			compatible = "st,stm32-i2c-v2";              /* in zephyr/dts/arm/st/l4/stm32l4.dtsi:266 */
			#address-cells = < 0x1 >;                    /* in zephyr/dts/arm/st/l4/stm32l4.dtsi:268 */
			#size-cells = < 0x0 >;                       /* in zephyr/dts/arm/st/l4/stm32l4.dtsi:269 */
			reg = < 0x40005c00 0x400 >;                  /* in zephyr/dts/arm/st/l4/stm32l4.dtsi:270 */
			clocks = < &rcc 0x58 0x800000 >;             /* in zephyr/dts/arm/st/l4/stm32l4.dtsi:271 */
			interrupts = < 0x48 0x0 >,
			             < 0x49 0x0 >;                   /* in zephyr/dts/arm/st/l4/stm32l4.dtsi:272 */
			interrupt-names = "event",
			                  "error";                   /* in zephyr/dts/arm/st/l4/stm32l4.dtsi:273 */
			pinctrl-0 = < &i2c3_scl_pc0 &i2c3_sda_pc1 >; /* in zephyr/boards/st/disco_l475_iot1/disco_l475_iot1.dts:180 */
			pinctrl-names = "default";                   /* in zephyr/boards/st/disco_l475_iot1/disco_l475_iot1.dts:181 */
			status = "okay";                             /* in zephyr/boards/st/disco_l475_iot1/disco_l475_iot1.dts:182 */
			clock-frequency = < 0x61a80 >;               /* in zephyr/boards/st/disco_l475_iot1/disco_l475_iot1.dts:183 */
			phandle = < 0x33 >;                          /* in zephyr/dts/arm/st/l4/stm32l4.dtsi:590 */
		};

		/* node '/soc/spi@a0001000' defined in zephyr/dts/arm/st/l4/stm32l4.dtsi:277 */
		quadspi: spi@a0001000 {
			compatible = "st,stm32-qspi";                                                                                       /* in zephyr/dts/arm/st/l4/stm32l4.dtsi:278 */
			#address-cells = < 0x1 >;                                                                                           /* in zephyr/dts/arm/st/l4/stm32l4.dtsi:279 */
			#size-cells = < 0x0 >;                                                                                              /* in zephyr/dts/arm/st/l4/stm32l4.dtsi:280 */
			reg = < 0xa0001000 0x400 >,
			      < 0x90000000 0x10000000 >;                                                                                    /* in zephyr/dts/arm/st/l4/stm32l4.dtsi:281 */
			interrupts = < 0x47 0x0 >;                                                                                          /* in zephyr/dts/arm/st/l4/stm32l4.dtsi:282 */
			clocks = < &rcc 0x50 0x100 >;                                                                                       /* in zephyr/dts/arm/st/l4/stm32l4.dtsi:283 */
			pinctrl-0 = < &quadspi_clk_pe10 &quadspi_ncs_pe11 &quadspi_bk1_io0_pe12 &quadspi_bk1_io1_pe13 &quadspi_bk1_io2_pe14
			              &quadspi_bk1_io3_pe15 >;                                                                              /* in zephyr/boards/st/disco_l475_iot1/disco_l475_iot1.dts:323 */
			pinctrl-names = "default";                                                                                          /* in zephyr/boards/st/disco_l475_iot1/disco_l475_iot1.dts:326 */
			dmas = < &dma1 0x5 0x5 0x0 >;                                                                                       /* in zephyr/boards/st/disco_l475_iot1/disco_l475_iot1.dts:327 */
			dma-names = "tx_rx";                                                                                                /* in zephyr/boards/st/disco_l475_iot1/disco_l475_iot1.dts:328 */
			status = "okay";                                                                                                    /* in zephyr/boards/st/disco_l475_iot1/disco_l475_iot1.dts:329 */

			/* node '/soc/spi@a0001000/qspi-nor-flash@0' defined in zephyr/boards/st/disco_l475_iot1/disco_l475_iot1.dts:331 */
			mx25r6435f: qspi-nor-flash@0 {
				compatible = "st,stm32-qspi-nor";   /* in zephyr/boards/st/disco_l475_iot1/disco_l475_iot1.dts:332 */
				reg = < 0x0 >;                      /* in zephyr/boards/st/disco_l475_iot1/disco_l475_iot1.dts:333 */
				size = < 0x4000000 >;               /* in zephyr/boards/st/disco_l475_iot1/disco_l475_iot1.dts:334 */
				qspi-max-frequency = < 0x2faf080 >; /* in zephyr/boards/st/disco_l475_iot1/disco_l475_iot1.dts:335 */
				cs-high-time = < 0x2 >;             /* in zephyr/boards/st/disco_l475_iot1/disco_l475_iot1.dts:336 */
				status = "okay";                    /* in zephyr/boards/st/disco_l475_iot1/disco_l475_iot1.dts:337 */

				/* node '/soc/spi@a0001000/qspi-nor-flash@0/partitions' defined in zephyr/boards/st/disco_l475_iot1/disco_l475_iot1.dts:339 */
				partitions {
					compatible = "fixed-partitions"; /* in zephyr/boards/st/disco_l475_iot1/disco_l475_iot1.dts:340 */
					#address-cells = < 0x1 >;        /* in zephyr/boards/st/disco_l475_iot1/disco_l475_iot1.dts:341 */
					#size-cells = < 0x1 >;           /* in zephyr/boards/st/disco_l475_iot1/disco_l475_iot1.dts:342 */

					/* node '/soc/spi@a0001000/qspi-nor-flash@0/partitions/partition@0' defined in zephyr/boards/st/disco_l475_iot1/disco_l475_iot1.dts:344 */
					slot1_partition: partition@0 {
						label = "image-1";     /* in zephyr/boards/st/disco_l475_iot1/disco_l475_iot1.dts:345 */
						reg = < 0x0 0xd8000 >; /* in zephyr/boards/st/disco_l475_iot1/disco_l475_iot1.dts:346 */
					};

					/* node '/soc/spi@a0001000/qspi-nor-flash@0/partitions/partition@d8000' defined in zephyr/boards/st/disco_l475_iot1/disco_l475_iot1.dts:349 */
					slot2_partition: partition@d8000 {
						label = "image-3";          /* in zephyr/boards/st/disco_l475_iot1/disco_l475_iot1.dts:350 */
						reg = < 0xd8000 0x700000 >; /* in zephyr/boards/st/disco_l475_iot1/disco_l475_iot1.dts:351 */
					};
				};
			};
		};

		/* node '/soc/spi@40013000' defined in zephyr/dts/arm/st/l4/stm32l4.dtsi:287 */
		spi1: arduino_spi: spi@40013000 {
			compatible = "st,stm32-spi-fifo",
			             "st,stm32-spi";                                 /* in zephyr/dts/arm/st/l4/stm32l4.dtsi:288 */
			#address-cells = < 0x1 >;                                    /* in zephyr/dts/arm/st/l4/stm32l4.dtsi:289 */
			#size-cells = < 0x0 >;                                       /* in zephyr/dts/arm/st/l4/stm32l4.dtsi:290 */
			reg = < 0x40013000 0x400 >;                                  /* in zephyr/dts/arm/st/l4/stm32l4.dtsi:291 */
			interrupts = < 0x23 0x5 >;                                   /* in zephyr/dts/arm/st/l4/stm32l4.dtsi:292 */
			clocks = < &rcc 0x60 0x1000 >;                               /* in zephyr/dts/arm/st/l4/stm32l4.dtsi:293 */
			pinctrl-0 = < &spi1_sck_pa5 &spi1_miso_pa6 &spi1_mosi_pa7 >; /* in zephyr/boards/st/disco_l475_iot1/disco_l475_iot1.dts:187 */
			pinctrl-names = "default";                                   /* in zephyr/boards/st/disco_l475_iot1/disco_l475_iot1.dts:188 */
			cs-gpios = < &gpioa 0x2 0x11 >;                              /* in zephyr/boards/st/disco_l475_iot1/disco_l475_iot1.dts:189 */
			status = "okay";                                             /* in zephyr/boards/st/disco_l475_iot1/disco_l475_iot1.dts:190 */
		};

		/* node '/soc/timers@40012c00' defined in zephyr/dts/arm/st/l4/stm32l4.dtsi:297 */
		timers1: timers@40012c00 {
			compatible = "st,stm32-timers"; /* in zephyr/dts/arm/st/l4/stm32l4.dtsi:298 */
			reg = < 0x40012c00 0x400 >;     /* in zephyr/dts/arm/st/l4/stm32l4.dtsi:299 */
			clocks = < &rcc 0x60 0x800 >,
			         < &rcc 0x9 0xff >;     /* in zephyr/dts/arm/st/l4/stm32l4.dtsi:300 */
			resets = < &rctl 0x80b >;       /* in zephyr/dts/arm/st/l4/stm32l4.dtsi:302 */
			interrupts = < 0x18 0x0 >,
			             < 0x19 0x0 >,
			             < 0x1a 0x0 >,
			             < 0x1b 0x0 >;      /* in zephyr/dts/arm/st/l4/stm32l4.dtsi:303 */
			interrupt-names = "brk",
			                  "up",
			                  "trgcom",
			                  "cc";         /* in zephyr/dts/arm/st/l4/stm32l4.dtsi:304 */
			st,prescaler = < 0x0 >;         /* in zephyr/dts/arm/st/l4/stm32l4.dtsi:305 */
			status = "disabled";            /* in zephyr/dts/arm/st/l4/stm32l4.dtsi:306 */

			/* node '/soc/timers@40012c00/pwm' defined in zephyr/dts/arm/st/l4/stm32l4.dtsi:308 */
			pwm {
				compatible = "st,stm32-pwm"; /* in zephyr/dts/arm/st/l4/stm32l4.dtsi:309 */
				status = "disabled";         /* in zephyr/dts/arm/st/l4/stm32l4.dtsi:310 */
				#pwm-cells = < 0x3 >;        /* in zephyr/dts/arm/st/l4/stm32l4.dtsi:311 */
			};

			/* node '/soc/timers@40012c00/qdec' defined in zephyr/dts/arm/st/l4/stm32l4.dtsi:314 */
			qdec {
				compatible = "st,stm32-qdec";    /* in zephyr/dts/arm/st/l4/stm32l4.dtsi:315 */
				st,input-filter-level = < 0x0 >; /* in zephyr/dts/arm/st/l4/stm32l4.dtsi:316 */
				status = "disabled";             /* in zephyr/dts/arm/st/l4/stm32l4.dtsi:317 */
			};
		};

		/* node '/soc/timers@40000000' defined in zephyr/dts/arm/st/l4/stm32l4.dtsi:321 */
		timers2: timers@40000000 {
			compatible = "st,stm32-timers"; /* in zephyr/dts/arm/st/l4/stm32l4.dtsi:322 */
			reg = < 0x40000000 0x400 >;     /* in zephyr/dts/arm/st/l4/stm32l4.dtsi:323 */
			clocks = < &rcc 0x58 0x1 >,
			         < &rcc 0x8 0xff >;     /* in zephyr/dts/arm/st/l4/stm32l4.dtsi:324 */
			resets = < &rctl 0x700 >;       /* in zephyr/dts/arm/st/l4/stm32l4.dtsi:326 */
			interrupts = < 0x1c 0x0 >;      /* in zephyr/dts/arm/st/l4/stm32l4.dtsi:327 */
			interrupt-names = "global";     /* in zephyr/dts/arm/st/l4/stm32l4.dtsi:328 */
			st,prescaler = < 0x2710 >;      /* in zephyr/boards/st/disco_l475_iot1/disco_l475_iot1.dts:251 */
			status = "okay";                /* in zephyr/boards/st/disco_l475_iot1/disco_l475_iot1.dts:252 */

			/* node '/soc/timers@40000000/pwm' defined in zephyr/dts/arm/st/l4/stm32l4.dtsi:332 */
			pwm2: pwm {
				compatible = "st,stm32-pwm";    /* in zephyr/dts/arm/st/l4/stm32l4.dtsi:333 */
				#pwm-cells = < 0x3 >;           /* in zephyr/dts/arm/st/l4/stm32l4.dtsi:335 */
				status = "okay";                /* in zephyr/boards/st/disco_l475_iot1/disco_l475_iot1.dts:255 */
				pinctrl-0 = < &tim2_ch1_pa15 >; /* in zephyr/boards/st/disco_l475_iot1/disco_l475_iot1.dts:256 */
				pinctrl-names = "default";      /* in zephyr/boards/st/disco_l475_iot1/disco_l475_iot1.dts:257 */
				phandle = < 0x35 >;             /* in zephyr/boards/st/disco_l475_iot1/disco_l475_iot1.dts:62 */
			};

			/* node '/soc/timers@40000000/counter' defined in zephyr/dts/arm/st/l4/stm32l4.dtsi:338 */
			counter {
				compatible = "st,stm32-counter"; /* in zephyr/dts/arm/st/l4/stm32l4.dtsi:339 */
				status = "disabled";             /* in zephyr/dts/arm/st/l4/stm32l4.dtsi:340 */
			};

			/* node '/soc/timers@40000000/qdec' defined in zephyr/dts/arm/st/l4/stm32l4.dtsi:343 */
			qdec {
				compatible = "st,stm32-qdec";    /* in zephyr/dts/arm/st/l4/stm32l4.dtsi:344 */
				st,input-filter-level = < 0x0 >; /* in zephyr/dts/arm/st/l4/stm32l4.dtsi:345 */
				status = "disabled";             /* in zephyr/dts/arm/st/l4/stm32l4.dtsi:346 */
			};
		};

		/* node '/soc/timers@40001000' defined in zephyr/dts/arm/st/l4/stm32l4.dtsi:350 */
		timers6: timers@40001000 {
			compatible = "st,stm32-timers"; /* in zephyr/dts/arm/st/l4/stm32l4.dtsi:351 */
			reg = < 0x40001000 0x400 >;     /* in zephyr/dts/arm/st/l4/stm32l4.dtsi:352 */
			clocks = < &rcc 0x58 0x10 >,
			         < &rcc 0x8 0xff >;     /* in zephyr/dts/arm/st/l4/stm32l4.dtsi:353 */
			resets = < &rctl 0x704 >;       /* in zephyr/dts/arm/st/l4/stm32l4.dtsi:355 */
			interrupts = < 0x36 0x0 >;      /* in zephyr/dts/arm/st/l4/stm32l4.dtsi:356 */
			interrupt-names = "global";     /* in zephyr/dts/arm/st/l4/stm32l4.dtsi:357 */
			st,prescaler = < 0x0 >;         /* in zephyr/dts/arm/st/l4/stm32l4.dtsi:358 */
			status = "disabled";            /* in zephyr/dts/arm/st/l4/stm32l4.dtsi:359 */

			/* node '/soc/timers@40001000/counter' defined in zephyr/dts/arm/st/l4/stm32l4.dtsi:361 */
			counter {
				compatible = "st,stm32-counter"; /* in zephyr/dts/arm/st/l4/stm32l4.dtsi:362 */
				status = "disabled";             /* in zephyr/dts/arm/st/l4/stm32l4.dtsi:363 */
			};
		};

		/* node '/soc/timers@40014000' defined in zephyr/dts/arm/st/l4/stm32l4.dtsi:367 */
		timers15: timers@40014000 {
			compatible = "st,stm32-timers"; /* in zephyr/dts/arm/st/l4/stm32l4.dtsi:368 */
			reg = < 0x40014000 0x400 >;     /* in zephyr/dts/arm/st/l4/stm32l4.dtsi:369 */
			clocks = < &rcc 0x60 0x10000 >,
			         < &rcc 0x9 0xff >;     /* in zephyr/dts/arm/st/l4/stm32l4.dtsi:370 */
			resets = < &rctl 0x810 >;       /* in zephyr/dts/arm/st/l4/stm32l4.dtsi:372 */
			interrupts = < 0x18 0x0 >;      /* in zephyr/dts/arm/st/l4/stm32l4.dtsi:373 */
			interrupt-names = "global";     /* in zephyr/dts/arm/st/l4/stm32l4.dtsi:374 */
			st,prescaler = < 0x2710 >;      /* in zephyr/boards/st/disco_l475_iot1/disco_l475_iot1.dts:262 */
			status = "okay";                /* in zephyr/boards/st/disco_l475_iot1/disco_l475_iot1.dts:263 */

			/* node '/soc/timers@40014000/pwm' defined in zephyr/dts/arm/st/l4/stm32l4.dtsi:378 */
			pwm15: pwm {
				compatible = "st,stm32-pwm";     /* in zephyr/dts/arm/st/l4/stm32l4.dtsi:379 */
				#pwm-cells = < 0x3 >;            /* in zephyr/dts/arm/st/l4/stm32l4.dtsi:381 */
				status = "okay";                 /* in zephyr/boards/st/disco_l475_iot1/disco_l475_iot1.dts:266 */
				pinctrl-0 = < &tim15_ch1_pb14 >; /* in zephyr/boards/st/disco_l475_iot1/disco_l475_iot1.dts:267 */
				pinctrl-names = "default";       /* in zephyr/boards/st/disco_l475_iot1/disco_l475_iot1.dts:268 */
				phandle = < 0x36 >;              /* in zephyr/boards/st/disco_l475_iot1/disco_l475_iot1.dts:67 */
			};

			/* node '/soc/timers@40014000/counter' defined in zephyr/dts/arm/st/l4/stm32l4.dtsi:384 */
			counter {
				compatible = "st,stm32-counter"; /* in zephyr/dts/arm/st/l4/stm32l4.dtsi:385 */
				status = "disabled";             /* in zephyr/dts/arm/st/l4/stm32l4.dtsi:386 */
			};
		};

		/* node '/soc/timers@40014400' defined in zephyr/dts/arm/st/l4/stm32l4.dtsi:390 */
		timers16: timers@40014400 {
			compatible = "st,stm32-timers"; /* in zephyr/dts/arm/st/l4/stm32l4.dtsi:391 */
			reg = < 0x40014400 0x400 >;     /* in zephyr/dts/arm/st/l4/stm32l4.dtsi:392 */
			clocks = < &rcc 0x60 0x20000 >,
			         < &rcc 0x9 0xff >;     /* in zephyr/dts/arm/st/l4/stm32l4.dtsi:393 */
			resets = < &rctl 0x811 >;       /* in zephyr/dts/arm/st/l4/stm32l4.dtsi:395 */
			interrupts = < 0x19 0x0 >;      /* in zephyr/dts/arm/st/l4/stm32l4.dtsi:396 */
			interrupt-names = "global";     /* in zephyr/dts/arm/st/l4/stm32l4.dtsi:397 */
			st,prescaler = < 0x0 >;         /* in zephyr/dts/arm/st/l4/stm32l4.dtsi:398 */
			status = "disabled";            /* in zephyr/dts/arm/st/l4/stm32l4.dtsi:399 */

			/* node '/soc/timers@40014400/pwm' defined in zephyr/dts/arm/st/l4/stm32l4.dtsi:401 */
			pwm {
				compatible = "st,stm32-pwm"; /* in zephyr/dts/arm/st/l4/stm32l4.dtsi:402 */
				status = "disabled";         /* in zephyr/dts/arm/st/l4/stm32l4.dtsi:403 */
				#pwm-cells = < 0x3 >;        /* in zephyr/dts/arm/st/l4/stm32l4.dtsi:404 */
			};

			/* node '/soc/timers@40014400/counter' defined in zephyr/dts/arm/st/l4/stm32l4.dtsi:407 */
			counter {
				compatible = "st,stm32-counter"; /* in zephyr/dts/arm/st/l4/stm32l4.dtsi:408 */
				status = "disabled";             /* in zephyr/dts/arm/st/l4/stm32l4.dtsi:409 */
			};
		};

		/* node '/soc/rtc@40002800' defined in zephyr/dts/arm/st/l4/stm32l4.dtsi:413 */
		rtc: rtc@40002800 {
			compatible = "st,stm32-rtc";       /* in zephyr/dts/arm/st/l4/stm32l4.dtsi:414 */
			reg = < 0x40002800 0x400 >;        /* in zephyr/dts/arm/st/l4/stm32l4.dtsi:415 */
			interrupts = < 0x29 0x0 >;         /* in zephyr/dts/arm/st/l4/stm32l4.dtsi:416 */
			prescaler = < 0x8000 >;            /* in zephyr/dts/arm/st/l4/stm32l4.dtsi:418 */
			alarms-count = < 0x2 >;            /* in zephyr/dts/arm/st/l4/stm32l4.dtsi:419 */
			alrm-exti-line = < 0x12 >;         /* in zephyr/dts/arm/st/l4/stm32l4.dtsi:420 */
			clocks = < &rcc 0x58 0x10000000 >,
			         < &rcc 0x3 0x2280090 >;   /* in zephyr/boards/st/disco_l475_iot1/disco_l475_iot1.dts:279 */
			status = "okay";                   /* in zephyr/boards/st/disco_l475_iot1/disco_l475_iot1.dts:281 */

			/* node '/soc/rtc@40002800/backup_regs' defined in zephyr/dts/arm/st/l4/stm32l471.dtsi:320 */
			bbram: backup_regs {
				compatible = "st,stm32-bbram"; /* in zephyr/dts/arm/st/l4/stm32l471.dtsi:321 */
				st,backup-regs = < 0x20 >;     /* in zephyr/dts/arm/st/l4/stm32l471.dtsi:322 */
				status = "disabled";           /* in zephyr/dts/arm/st/l4/stm32l471.dtsi:323 */
			};
		};

		/* node '/soc/adc@50040000' defined in zephyr/dts/arm/st/l4/stm32l4.dtsi:424 */
		adc1: adc@50040000 {
			compatible = "st,stm32-adc";                                               /* in zephyr/dts/arm/st/l4/stm32l4.dtsi:425 */
			reg = < 0x50040000 0x100 >;                                                /* in zephyr/dts/arm/st/l4/stm32l4.dtsi:426 */
			clocks = < &rcc 0x4c 0x2000 >;                                             /* in zephyr/dts/arm/st/l4/stm32l4.dtsi:427 */
			clock-names = "adcx";                                                      /* in zephyr/dts/arm/st/l4/stm32l4.dtsi:428 */
			interrupts = < 0x12 0x0 >;                                                 /* in zephyr/dts/arm/st/l4/stm32l4.dtsi:429 */
			#io-channel-cells = < 0x1 >;                                               /* in zephyr/dts/arm/st/l4/stm32l4.dtsi:430 */
			resolutions = < 0x60630c 0x51630c 0x42630c 0x33630c >;                     /* in zephyr/dts/arm/st/l4/stm32l4.dtsi:431 */
			sampling-times = < 0x3 0x7 0xd 0x19 0x30 0x5d 0xf8 0x281 >;                /* in zephyr/dts/arm/st/l4/stm32l4.dtsi:435 */
			st,adc-sequencer = "programmable";                                         /* in zephyr/dts/arm/st/l4/stm32l4.dtsi:436 */
			st,adc-oversampler = "minimal";                                            /* in zephyr/dts/arm/st/l4/stm32l4.dtsi:437 */
			st,adc-internal-regulator = "startup-sw-delay";                            /* in zephyr/dts/arm/st/l4/stm32l4.dtsi:438 */
			st,adc-has-deep-powerdown;                                                 /* in zephyr/dts/arm/st/l4/stm32l4.dtsi:439 */
			st,adc-has-differential-support;                                           /* in zephyr/dts/arm/st/l4/stm32l4.dtsi:440 */
			pinctrl-0 = < &adc1_in3_pc2 &adc1_in4_pc3 &adc1_in13_pc4 &adc1_in14_pc5 >; /* in zephyr/boards/st/disco_l475_iot1/disco_l475_iot1.dts:300 */
			pinctrl-names = "default";                                                 /* in zephyr/boards/st/disco_l475_iot1/disco_l475_iot1.dts:302 */
			st,adc-clock-source = "SYNC";                                              /* in zephyr/boards/st/disco_l475_iot1/disco_l475_iot1.dts:303 */
			st,adc-prescaler = < 0x4 >;                                                /* in zephyr/boards/st/disco_l475_iot1/disco_l475_iot1.dts:304 */
			status = "okay";                                                           /* in zephyr/boards/st/disco_l475_iot1/disco_l475_iot1.dts:305 */
			phandle = < 0x31 >;                                                        /* in zephyr/dts/arm/st/l4/stm32l4.dtsi:559 */
		};

		/* node '/soc/adc@50040100' defined in zephyr/dts/arm/st/l4/stm32l4.dtsi:444 */
		adc2: adc@50040100 {
			compatible = "st,stm32-adc";                                /* in zephyr/dts/arm/st/l4/stm32l4.dtsi:445 */
			reg = < 0x50040100 0x100 >;                                 /* in zephyr/dts/arm/st/l4/stm32l4.dtsi:446 */
			clocks = < &rcc 0x4c 0x2000 >;                              /* in zephyr/dts/arm/st/l4/stm32l4.dtsi:447 */
			clock-names = "adcx";                                       /* in zephyr/dts/arm/st/l4/stm32l4.dtsi:448 */
			interrupts = < 0x12 0x0 >;                                  /* in zephyr/dts/arm/st/l4/stm32l4.dtsi:449 */
			#io-channel-cells = < 0x1 >;                                /* in zephyr/dts/arm/st/l4/stm32l4.dtsi:450 */
			resolutions = < 0x60630c 0x51630c 0x42630c 0x33630c >;      /* in zephyr/dts/arm/st/l4/stm32l4.dtsi:451 */
			sampling-times = < 0x3 0x7 0xd 0x19 0x30 0x5d 0xf8 0x281 >; /* in zephyr/dts/arm/st/l4/stm32l4.dtsi:455 */
			st,adc-sequencer = "programmable";                          /* in zephyr/dts/arm/st/l4/stm32l4.dtsi:456 */
			st,adc-oversampler = "minimal";                             /* in zephyr/dts/arm/st/l4/stm32l4.dtsi:457 */
			st,adc-internal-regulator = "startup-sw-delay";             /* in zephyr/dts/arm/st/l4/stm32l4.dtsi:458 */
			st,adc-has-deep-powerdown;                                  /* in zephyr/dts/arm/st/l4/stm32l4.dtsi:459 */
			st,adc-has-differential-support;                            /* in zephyr/dts/arm/st/l4/stm32l4.dtsi:460 */
			status = "disabled";                                        /* in zephyr/dts/arm/st/l4/stm32l4.dtsi:461 */
		};

		/* node '/soc/dma@40020000' defined in zephyr/dts/arm/st/l4/stm32l4.dtsi:464 */
		dma1: dma@40020000 {
			compatible = "st,stm32-dma-v2";                                             /* in zephyr/dts/arm/st/l4/stm32l4.dtsi:465 */
			#dma-cells = < 0x3 >;                                                       /* in zephyr/dts/arm/st/l4/stm32l4.dtsi:466 */
			reg = < 0x40020000 0x400 >;                                                 /* in zephyr/dts/arm/st/l4/stm32l4.dtsi:467 */
			interrupts = < 0xb 0x0 0xc 0x0 0xd 0x0 0xe 0x0 0xf 0x0 0x10 0x0 0x11 0x0 >; /* in zephyr/dts/arm/st/l4/stm32l4.dtsi:468 */
			clocks = < &rcc 0x48 0x1 >;                                                 /* in zephyr/dts/arm/st/l4/stm32l4.dtsi:469 */
			dma-requests = < 0x7 >;                                                     /* in zephyr/dts/arm/st/l4/stm32l4.dtsi:470 */
			status = "okay";                                                            /* in zephyr/boards/st/disco_l475_iot1/disco_l475_iot1.dts:319 */
			phandle = < 0x11 >;                                                         /* in zephyr/boards/st/disco_l475_iot1/disco_l475_iot1.dts:327 */
		};

		/* node '/soc/dma@40020400' defined in zephyr/dts/arm/st/l4/stm32l4.dtsi:474 */
		dma2: dma@40020400 {
			compatible = "st,stm32-dma-v2";                                                  /* in zephyr/dts/arm/st/l4/stm32l4.dtsi:475 */
			#dma-cells = < 0x3 >;                                                            /* in zephyr/dts/arm/st/l4/stm32l4.dtsi:476 */
			reg = < 0x40020400 0x400 >;                                                      /* in zephyr/dts/arm/st/l4/stm32l4.dtsi:477 */
			interrupts = < 0x38 0x0 0x39 0x0 0x3a 0x0 0x3b 0x0 0x3c 0x0 0x44 0x0 0x45 0x0 >; /* in zephyr/dts/arm/st/l4/stm32l4.dtsi:478 */
			clocks = < &rcc 0x48 0x2 >;                                                      /* in zephyr/dts/arm/st/l4/stm32l4.dtsi:479 */
			dma-requests = < 0x7 >;                                                          /* in zephyr/dts/arm/st/l4/stm32l4.dtsi:480 */
			status = "disabled";                                                             /* in zephyr/dts/arm/st/l4/stm32l4.dtsi:481 */
			phandle = < 0x1c >;                                                              /* in zephyr/dts/arm/st/l4/stm32l4_sai.dtsi:16 */
		};

		/* node '/soc/timers@40007c00' defined in zephyr/dts/arm/st/l4/stm32l4.dtsi:484 */
		lptim1: stm32_lp_tick_source: timers@40007c00 {
			compatible = "st,stm32-lptim";     /* in zephyr/dts/arm/st/l4/stm32l4.dtsi:485 */
			#address-cells = < 0x1 >;          /* in zephyr/dts/arm/st/l4/stm32l4.dtsi:487 */
			#size-cells = < 0x0 >;             /* in zephyr/dts/arm/st/l4/stm32l4.dtsi:488 */
			reg = < 0x40007c00 0x400 >;        /* in zephyr/dts/arm/st/l4/stm32l4.dtsi:489 */
			interrupts = < 0x41 0x1 >;         /* in zephyr/dts/arm/st/l4/stm32l4.dtsi:490 */
			interrupt-names = "wakeup";        /* in zephyr/dts/arm/st/l4/stm32l4.dtsi:491 */
			clocks = < &rcc 0x58 0x80000000 >,
			         < &rcc 0x2 0x3320088 >;   /* in zephyr/boards/st/disco_l475_iot1/disco_l475_iot1.dts:273 */
			status = "okay";                   /* in zephyr/boards/st/disco_l475_iot1/disco_l475_iot1.dts:275 */
		};

		/* node '/soc/timers@40009400' defined in zephyr/dts/arm/st/l4/stm32l4.dtsi:495 */
		lptim2: timers@40009400 {
			compatible = "st,stm32-lptim"; /* in zephyr/dts/arm/st/l4/stm32l4.dtsi:496 */
			#address-cells = < 0x1 >;      /* in zephyr/dts/arm/st/l4/stm32l4.dtsi:497 */
			#size-cells = < 0x0 >;         /* in zephyr/dts/arm/st/l4/stm32l4.dtsi:498 */
			reg = < 0x40009400 0x400 >;    /* in zephyr/dts/arm/st/l4/stm32l4.dtsi:499 */
			clocks = < &rcc 0x5c 0x20 >;   /* in zephyr/dts/arm/st/l4/stm32l4.dtsi:500 */
			interrupts = < 0x42 0x1 >;     /* in zephyr/dts/arm/st/l4/stm32l4.dtsi:501 */
			interrupt-names = "wakeup";    /* in zephyr/dts/arm/st/l4/stm32l4.dtsi:502 */
			status = "disabled";           /* in zephyr/dts/arm/st/l4/stm32l4.dtsi:503 */
		};

		/* node '/soc/rng@50060800' defined in zephyr/dts/arm/st/l4/stm32l4.dtsi:506 */
		rng: rng@50060800 {
			compatible = "st,stm32-rng";     /* in zephyr/dts/arm/st/l4/stm32l4.dtsi:507 */
			reg = < 0x50060800 0x400 >;      /* in zephyr/dts/arm/st/l4/stm32l4.dtsi:508 */
			interrupts = < 0x50 0x0 >;       /* in zephyr/dts/arm/st/l4/stm32l4.dtsi:509 */
			clocks = < &rcc 0x4c 0x40000 >,
			         < &rcc 0x6 0x33a0088 >; /* in zephyr/dts/arm/st/l4/stm32l4.dtsi:510 */
			status = "okay";                 /* in zephyr/boards/st/disco_l475_iot1/disco_l475_iot1.dts:296 */
		};

		/* node '/soc/power@40007000' defined in zephyr/dts/arm/st/l4/stm32l4.dtsi:518 */
		pwr: power@40007000 {
			compatible = "st,stm32-pwr"; /* in zephyr/dts/arm/st/l4/stm32l4.dtsi:519 */
			reg = < 0x40007000 0x400 >;  /* in zephyr/dts/arm/st/l4/stm32l4.dtsi:520 */
			status = "disabled";         /* in zephyr/dts/arm/st/l4/stm32l4.dtsi:521 */
			wkup-pins-nb = < 0x5 >;      /* in zephyr/dts/arm/st/l4/stm32l4.dtsi:523 */
			wkup-pins-pol;               /* in zephyr/dts/arm/st/l4/stm32l4.dtsi:524 */
			wkup-pins-pupd;              /* in zephyr/dts/arm/st/l4/stm32l4.dtsi:525 */
			#address-cells = < 0x1 >;    /* in zephyr/dts/arm/st/l4/stm32l4.dtsi:527 */
			#size-cells = < 0x0 >;       /* in zephyr/dts/arm/st/l4/stm32l4.dtsi:528 */

			/* node '/soc/power@40007000/wkup-pin@1' defined in zephyr/dts/arm/st/l4/stm32l4.dtsi:530 */
			wkup-pin@1 {
				reg = < 0x1 >; /* in zephyr/dts/arm/st/l4/stm32l4.dtsi:531 */
			};

			/* node '/soc/power@40007000/wkup-pin@2' defined in zephyr/dts/arm/st/l4/stm32l4.dtsi:534 */
			wkup-pin@2 {
				reg = < 0x2 >; /* in zephyr/dts/arm/st/l4/stm32l4.dtsi:535 */
			};

			/* node '/soc/power@40007000/wkup-pin@3' defined in zephyr/dts/arm/st/l4/stm32l4.dtsi:538 */
			wkup-pin@3 {
				reg = < 0x3 >; /* in zephyr/dts/arm/st/l4/stm32l4.dtsi:539 */
			};

			/* node '/soc/power@40007000/wkup-pin@4' defined in zephyr/dts/arm/st/l4/stm32l4.dtsi:542 */
			wkup-pin@4 {
				reg = < 0x4 >; /* in zephyr/dts/arm/st/l4/stm32l4.dtsi:543 */
			};

			/* node '/soc/power@40007000/wkup-pin@5' defined in zephyr/dts/arm/st/l4/stm32l4.dtsi:546 */
			wkup-pin@5 {
				reg = < 0x5 >; /* in zephyr/dts/arm/st/l4/stm32l4.dtsi:547 */
			};
		};

		/* node '/soc/sai1@40015404' defined in zephyr/dts/arm/st/l4/stm32l4_sai.dtsi:9 */
		sai1_a: sai1@40015404 {
			compatible = "st,stm32-sai";      /* in zephyr/dts/arm/st/l4/stm32l4_sai.dtsi:10 */
			#address-cells = < 0x1 >;         /* in zephyr/dts/arm/st/l4/stm32l4_sai.dtsi:11 */
			#size-cells = < 0x0 >;            /* in zephyr/dts/arm/st/l4/stm32l4_sai.dtsi:12 */
			reg = < 0x40015404 0x20 >;        /* in zephyr/dts/arm/st/l4/stm32l4_sai.dtsi:13 */
			clocks = < &rcc 0x60 0x200000 >,
			         < &rcc 0xd 0x360088 >;   /* in zephyr/dts/arm/st/l4/stm32l4_sai.dtsi:14 */
			dmas = < &dma2 0x1 0x1 0x22800 >; /* in zephyr/dts/arm/st/l4/stm32l4_sai.dtsi:16 */
			status = "disabled";              /* in zephyr/dts/arm/st/l4/stm32l4_sai.dtsi:18 */
		};

		/* node '/soc/sai1@40015424' defined in zephyr/dts/arm/st/l4/stm32l4_sai.dtsi:21 */
		sai1_b: sai1@40015424 {
			compatible = "st,stm32-sai";      /* in zephyr/dts/arm/st/l4/stm32l4_sai.dtsi:22 */
			#address-cells = < 0x1 >;         /* in zephyr/dts/arm/st/l4/stm32l4_sai.dtsi:23 */
			#size-cells = < 0x0 >;            /* in zephyr/dts/arm/st/l4/stm32l4_sai.dtsi:24 */
			reg = < 0x40015424 0x20 >;        /* in zephyr/dts/arm/st/l4/stm32l4_sai.dtsi:25 */
			clocks = < &rcc 0x60 0x200000 >,
			         < &rcc 0xd 0x360088 >;   /* in zephyr/dts/arm/st/l4/stm32l4_sai.dtsi:26 */
			dmas = < &dma2 0x2 0x1 0x22800 >; /* in zephyr/dts/arm/st/l4/stm32l4_sai.dtsi:28 */
			status = "disabled";              /* in zephyr/dts/arm/st/l4/stm32l4_sai.dtsi:30 */
		};

		/* node '/soc/serial@40004800' defined in zephyr/dts/arm/st/l4/stm32l471.dtsi:62 */
		usart3: serial@40004800 {
			compatible = "st,stm32-usart",
			             "st,stm32-uart";   /* in zephyr/dts/arm/st/l4/stm32l471.dtsi:63 */
			reg = < 0x40004800 0x400 >;     /* in zephyr/dts/arm/st/l4/stm32l471.dtsi:64 */
			clocks = < &rcc 0x58 0x40000 >; /* in zephyr/dts/arm/st/l4/stm32l471.dtsi:65 */
			resets = < &rctl 0x712 >;       /* in zephyr/dts/arm/st/l4/stm32l471.dtsi:66 */
			interrupts = < 0x27 0x0 >;      /* in zephyr/dts/arm/st/l4/stm32l471.dtsi:67 */
			status = "disabled";            /* in zephyr/dts/arm/st/l4/stm32l471.dtsi:68 */
		};

		/* node '/soc/serial@40004c00' defined in zephyr/dts/arm/st/l4/stm32l471.dtsi:71 */
		uart4: arduino_serial: serial@40004c00 {
			compatible = "st,stm32-uart";                /* in zephyr/dts/arm/st/l4/stm32l471.dtsi:72 */
			reg = < 0x40004c00 0x400 >;                  /* in zephyr/dts/arm/st/l4/stm32l471.dtsi:73 */
			clocks = < &rcc 0x58 0x80000 >;              /* in zephyr/dts/arm/st/l4/stm32l471.dtsi:74 */
			resets = < &rctl 0x713 >;                    /* in zephyr/dts/arm/st/l4/stm32l471.dtsi:75 */
			interrupts = < 0x34 0x0 >;                   /* in zephyr/dts/arm/st/l4/stm32l471.dtsi:76 */
			pinctrl-0 = < &uart4_tx_pa0 &uart4_rx_pa1 >; /* in zephyr/boards/st/disco_l475_iot1/disco_l475_iot1.dts:131 */
			pinctrl-names = "default";                   /* in zephyr/boards/st/disco_l475_iot1/disco_l475_iot1.dts:132 */
			current-speed = < 0x1c200 >;                 /* in zephyr/boards/st/disco_l475_iot1/disco_l475_iot1.dts:133 */
			status = "okay";                             /* in zephyr/boards/st/disco_l475_iot1/disco_l475_iot1.dts:134 */
		};

		/* node '/soc/serial@40005000' defined in zephyr/dts/arm/st/l4/stm32l471.dtsi:80 */
		uart5: serial@40005000 {
			compatible = "st,stm32-uart";    /* in zephyr/dts/arm/st/l4/stm32l471.dtsi:81 */
			reg = < 0x40005000 0x400 >;      /* in zephyr/dts/arm/st/l4/stm32l471.dtsi:82 */
			clocks = < &rcc 0x58 0x100000 >; /* in zephyr/dts/arm/st/l4/stm32l471.dtsi:83 */
			resets = < &rctl 0x714 >;        /* in zephyr/dts/arm/st/l4/stm32l471.dtsi:84 */
			interrupts = < 0x35 0x0 >;       /* in zephyr/dts/arm/st/l4/stm32l471.dtsi:85 */
			status = "disabled";             /* in zephyr/dts/arm/st/l4/stm32l471.dtsi:86 */
		};

		/* node '/soc/i2c@40005800' defined in zephyr/dts/arm/st/l4/stm32l471.dtsi:89 */
		i2c2: i2c@40005800 {
			compatible = "st,stm32-i2c-v2";                /* in zephyr/dts/arm/st/l4/stm32l471.dtsi:90 */
			#address-cells = < 0x1 >;                      /* in zephyr/dts/arm/st/l4/stm32l471.dtsi:92 */
			#size-cells = < 0x0 >;                         /* in zephyr/dts/arm/st/l4/stm32l471.dtsi:93 */
			reg = < 0x40005800 0x400 >;                    /* in zephyr/dts/arm/st/l4/stm32l471.dtsi:94 */
			clocks = < &rcc 0x58 0x400000 >;               /* in zephyr/dts/arm/st/l4/stm32l471.dtsi:95 */
			interrupts = < 0x21 0x0 >,
			             < 0x22 0x0 >;                     /* in zephyr/dts/arm/st/l4/stm32l471.dtsi:96 */
			interrupt-names = "event",
			                  "error";                     /* in zephyr/dts/arm/st/l4/stm32l471.dtsi:97 */
			pinctrl-0 = < &i2c2_scl_pb10 &i2c2_sda_pb11 >; /* in zephyr/boards/st/disco_l475_iot1/disco_l475_iot1.dts:145 */
			pinctrl-names = "default";                     /* in zephyr/boards/st/disco_l475_iot1/disco_l475_iot1.dts:146 */
			status = "okay";                               /* in zephyr/boards/st/disco_l475_iot1/disco_l475_iot1.dts:147 */
			clock-frequency = < 0x61a80 >;                 /* in zephyr/boards/st/disco_l475_iot1/disco_l475_iot1.dts:148 */
			phandle = < 0x34 >;                            /* in zephyr/dts/arm/st/l4/stm32l471.dtsi:336 */

			/* node '/soc/i2c@40005800/lis3mdl-magn@1e' defined in zephyr/boards/st/disco_l475_iot1/disco_l475_iot1.dts:150 */
			lis3mdl-magn@1e {
				compatible = "st,lis3mdl-magn"; /* in zephyr/boards/st/disco_l475_iot1/disco_l475_iot1.dts:151 */
				reg = < 0x1e >;                 /* in zephyr/boards/st/disco_l475_iot1/disco_l475_iot1.dts:152 */
			};

			/* node '/soc/i2c@40005800/hts221@5f' defined in zephyr/boards/st/disco_l475_iot1/disco_l475_iot1.dts:155 */
			hts221@5f {
				compatible = "st,hts221";        /* in zephyr/boards/st/disco_l475_iot1/disco_l475_iot1.dts:156 */
				reg = < 0x5f >;                  /* in zephyr/boards/st/disco_l475_iot1/disco_l475_iot1.dts:157 */
				drdy-gpios = < &gpiod 0xf 0x0 >; /* in zephyr/boards/st/disco_l475_iot1/disco_l475_iot1.dts:158 */
			};

			/* node '/soc/i2c@40005800/lps22hb-press@5d' defined in zephyr/boards/st/disco_l475_iot1/disco_l475_iot1.dts:161 */
			lps22hb-press@5d {
				compatible = "st,lps22hb-press"; /* in zephyr/boards/st/disco_l475_iot1/disco_l475_iot1.dts:162 */
				reg = < 0x5d >;                  /* in zephyr/boards/st/disco_l475_iot1/disco_l475_iot1.dts:163 */
			};

			/* node '/soc/i2c@40005800/lsm6dsl@6a' defined in zephyr/boards/st/disco_l475_iot1/disco_l475_iot1.dts:166 */
			lsm6dsl: lsm6dsl@6a {
				compatible = "st,lsm6dsl";      /* in zephyr/boards/st/disco_l475_iot1/disco_l475_iot1.dts:167 */
				reg = < 0x6a >;                 /* in zephyr/boards/st/disco_l475_iot1/disco_l475_iot1.dts:168 */
				irq-gpios = < &gpiod 0xb 0x0 >; /* in zephyr/boards/st/disco_l475_iot1/disco_l475_iot1.dts:169 */
			};

			/* node '/soc/i2c@40005800/vl53l0x@29' defined in zephyr/boards/st/disco_l475_iot1/disco_l475_iot1.dts:172 */
			vl53l0x@29 {
				compatible = "st,vl53l0x";        /* in zephyr/boards/st/disco_l475_iot1/disco_l475_iot1.dts:173 */
				reg = < 0x29 >;                   /* in zephyr/boards/st/disco_l475_iot1/disco_l475_iot1.dts:174 */
				xshut-gpios = < &gpioc 0x6 0x1 >; /* in zephyr/boards/st/disco_l475_iot1/disco_l475_iot1.dts:175 */
			};
		};

		/* node '/soc/spi@40003800' defined in zephyr/dts/arm/st/l4/stm32l471.dtsi:101 */
		spi2: spi@40003800 {
			compatible = "st,stm32-spi-fifo",
			             "st,stm32-spi";      /* in zephyr/dts/arm/st/l4/stm32l471.dtsi:102 */
			#address-cells = < 0x1 >;         /* in zephyr/dts/arm/st/l4/stm32l471.dtsi:103 */
			#size-cells = < 0x0 >;            /* in zephyr/dts/arm/st/l4/stm32l471.dtsi:104 */
			reg = < 0x40003800 0x400 >;       /* in zephyr/dts/arm/st/l4/stm32l471.dtsi:105 */
			clocks = < &rcc 0x58 0x4000 >;    /* in zephyr/dts/arm/st/l4/stm32l471.dtsi:106 */
			interrupts = < 0x24 0x5 >;        /* in zephyr/dts/arm/st/l4/stm32l471.dtsi:107 */
			status = "disabled";              /* in zephyr/dts/arm/st/l4/stm32l471.dtsi:108 */
		};

		/* node '/soc/spi@40003c00' defined in zephyr/dts/arm/st/l4/stm32l471.dtsi:111 */
		spi3: spi@40003c00 {
			compatible = "st,stm32-spi-fifo",
			             "st,stm32-spi";                                    /* in zephyr/dts/arm/st/l4/stm32l471.dtsi:112 */
			#address-cells = < 0x1 >;                                       /* in zephyr/dts/arm/st/l4/stm32l471.dtsi:113 */
			#size-cells = < 0x0 >;                                          /* in zephyr/dts/arm/st/l4/stm32l471.dtsi:114 */
			reg = < 0x40003c00 0x400 >;                                     /* in zephyr/dts/arm/st/l4/stm32l471.dtsi:115 */
			clocks = < &rcc 0x58 0x8000 >;                                  /* in zephyr/dts/arm/st/l4/stm32l471.dtsi:116 */
			interrupts = < 0x33 0x5 >;                                      /* in zephyr/dts/arm/st/l4/stm32l471.dtsi:117 */
			status = "okay";                                                /* in zephyr/boards/st/disco_l475_iot1/disco_l475_iot1.dts:198 */
			pinctrl-0 = < &spi3_sck_pc10 &spi3_miso_pc11 &spi3_mosi_pc12 >; /* in zephyr/boards/st/disco_l475_iot1/disco_l475_iot1.dts:200 */
			pinctrl-names = "default";                                      /* in zephyr/boards/st/disco_l475_iot1/disco_l475_iot1.dts:201 */
			cs-gpios = < &gpiod 0xd 0x1 >,
			           < &gpioe 0x0 0x1 >;                                  /* in zephyr/boards/st/disco_l475_iot1/disco_l475_iot1.dts:203 */

			/* node '/soc/spi@40003c00/spbtle-rf@0' defined in zephyr/boards/st/disco_l475_iot1/disco_l475_iot1.dts:206 */
			hci_spi: spbtle-rf@0 {
				compatible = "st,hci-spi-v1";     /* in zephyr/boards/st/disco_l475_iot1/disco_l475_iot1.dts:207 */
				reg = < 0x0 >;                    /* in zephyr/boards/st/disco_l475_iot1/disco_l475_iot1.dts:208 */
				reset-gpios = < &gpioa 0x8 0x1 >; /* in zephyr/boards/st/disco_l475_iot1/disco_l475_iot1.dts:209 */
				irq-gpios = < &gpioe 0x6 0x20 >;  /* in zephyr/boards/st/disco_l475_iot1/disco_l475_iot1.dts:210 */
				spi-max-frequency = < 0x1e8480 >; /* in zephyr/boards/st/disco_l475_iot1/disco_l475_iot1.dts:211 */
				spi-hold-cs;                      /* in zephyr/boards/st/disco_l475_iot1/disco_l475_iot1.dts:212 */
			};

			/* node '/soc/spi@40003c00/ism43362@1' defined in zephyr/boards/st/disco_l475_iot1/disco_l475_iot1.dts:215 */
			wifi0: ism43362@1 {
				compatible = "inventek,eswifi";    /* in zephyr/boards/st/disco_l475_iot1/disco_l475_iot1.dts:216 */
				spi-max-frequency = < 0x1e8480 >;  /* in zephyr/boards/st/disco_l475_iot1/disco_l475_iot1.dts:217 */
				reg = < 0x1 >;                     /* in zephyr/boards/st/disco_l475_iot1/disco_l475_iot1.dts:218 */
				resetn-gpios = < &gpioe 0x8 0x0 >; /* in zephyr/boards/st/disco_l475_iot1/disco_l475_iot1.dts:219 */
				boot0-gpios = < &gpiob 0xc 0x0 >;  /* in zephyr/boards/st/disco_l475_iot1/disco_l475_iot1.dts:220 */
				wakeup-gpios = < &gpiob 0xd 0x0 >; /* in zephyr/boards/st/disco_l475_iot1/disco_l475_iot1.dts:221 */
				data-gpios = < &gpioe 0x1 0x0 >;   /* in zephyr/boards/st/disco_l475_iot1/disco_l475_iot1.dts:222 */
			};
		};

		/* node '/soc/timers@40000400' defined in zephyr/dts/arm/st/l4/stm32l471.dtsi:121 */
		timers3: timers@40000400 {
			compatible = "st,stm32-timers"; /* in zephyr/dts/arm/st/l4/stm32l471.dtsi:122 */
			reg = < 0x40000400 0x400 >;     /* in zephyr/dts/arm/st/l4/stm32l471.dtsi:123 */
			clocks = < &rcc 0x58 0x2 >,
			         < &rcc 0x8 0xff >;     /* in zephyr/dts/arm/st/l4/stm32l471.dtsi:124 */
			resets = < &rctl 0x701 >;       /* in zephyr/dts/arm/st/l4/stm32l471.dtsi:126 */
			interrupts = < 0x1d 0x0 >;      /* in zephyr/dts/arm/st/l4/stm32l471.dtsi:127 */
			interrupt-names = "global";     /* in zephyr/dts/arm/st/l4/stm32l471.dtsi:128 */
			st,prescaler = < 0x0 >;         /* in zephyr/dts/arm/st/l4/stm32l471.dtsi:129 */
			status = "disabled";            /* in zephyr/dts/arm/st/l4/stm32l471.dtsi:130 */

			/* node '/soc/timers@40000400/pwm' defined in zephyr/dts/arm/st/l4/stm32l471.dtsi:132 */
			pwm {
				compatible = "st,stm32-pwm"; /* in zephyr/dts/arm/st/l4/stm32l471.dtsi:133 */
				status = "disabled";         /* in zephyr/dts/arm/st/l4/stm32l471.dtsi:134 */
				#pwm-cells = < 0x3 >;        /* in zephyr/dts/arm/st/l4/stm32l471.dtsi:135 */
			};

			/* node '/soc/timers@40000400/counter' defined in zephyr/dts/arm/st/l4/stm32l471.dtsi:138 */
			counter {
				compatible = "st,stm32-counter"; /* in zephyr/dts/arm/st/l4/stm32l471.dtsi:139 */
				status = "disabled";             /* in zephyr/dts/arm/st/l4/stm32l471.dtsi:140 */
			};

			/* node '/soc/timers@40000400/qdec' defined in zephyr/dts/arm/st/l4/stm32l471.dtsi:143 */
			qdec {
				compatible = "st,stm32-qdec";    /* in zephyr/dts/arm/st/l4/stm32l471.dtsi:144 */
				st,input-filter-level = < 0x0 >; /* in zephyr/dts/arm/st/l4/stm32l471.dtsi:145 */
				status = "disabled";             /* in zephyr/dts/arm/st/l4/stm32l471.dtsi:146 */
			};
		};

		/* node '/soc/timers@40000800' defined in zephyr/dts/arm/st/l4/stm32l471.dtsi:150 */
		timers4: timers@40000800 {
			compatible = "st,stm32-timers"; /* in zephyr/dts/arm/st/l4/stm32l471.dtsi:151 */
			reg = < 0x40000800 0x400 >;     /* in zephyr/dts/arm/st/l4/stm32l471.dtsi:152 */
			clocks = < &rcc 0x58 0x4 >,
			         < &rcc 0x8 0xff >;     /* in zephyr/dts/arm/st/l4/stm32l471.dtsi:153 */
			resets = < &rctl 0x702 >;       /* in zephyr/dts/arm/st/l4/stm32l471.dtsi:155 */
			interrupts = < 0x1e 0x0 >;      /* in zephyr/dts/arm/st/l4/stm32l471.dtsi:156 */
			interrupt-names = "global";     /* in zephyr/dts/arm/st/l4/stm32l471.dtsi:157 */
			st,prescaler = < 0x0 >;         /* in zephyr/dts/arm/st/l4/stm32l471.dtsi:158 */
			status = "disabled";            /* in zephyr/dts/arm/st/l4/stm32l471.dtsi:159 */

			/* node '/soc/timers@40000800/pwm' defined in zephyr/dts/arm/st/l4/stm32l471.dtsi:161 */
			pwm {
				compatible = "st,stm32-pwm"; /* in zephyr/dts/arm/st/l4/stm32l471.dtsi:162 */
				status = "disabled";         /* in zephyr/dts/arm/st/l4/stm32l471.dtsi:163 */
				#pwm-cells = < 0x3 >;        /* in zephyr/dts/arm/st/l4/stm32l471.dtsi:164 */
			};

			/* node '/soc/timers@40000800/counter' defined in zephyr/dts/arm/st/l4/stm32l471.dtsi:167 */
			counter {
				compatible = "st,stm32-counter"; /* in zephyr/dts/arm/st/l4/stm32l471.dtsi:168 */
				status = "disabled";             /* in zephyr/dts/arm/st/l4/stm32l471.dtsi:169 */
			};

			/* node '/soc/timers@40000800/qdec' defined in zephyr/dts/arm/st/l4/stm32l471.dtsi:172 */
			qdec {
				compatible = "st,stm32-qdec";    /* in zephyr/dts/arm/st/l4/stm32l471.dtsi:173 */
				st,input-filter-level = < 0x0 >; /* in zephyr/dts/arm/st/l4/stm32l471.dtsi:174 */
				status = "disabled";             /* in zephyr/dts/arm/st/l4/stm32l471.dtsi:175 */
			};
		};

		/* node '/soc/timers@40000c00' defined in zephyr/dts/arm/st/l4/stm32l471.dtsi:179 */
		timers5: timers@40000c00 {
			compatible = "st,stm32-timers"; /* in zephyr/dts/arm/st/l4/stm32l471.dtsi:180 */
			reg = < 0x40000c00 0x400 >;     /* in zephyr/dts/arm/st/l4/stm32l471.dtsi:181 */
			clocks = < &rcc 0x58 0x8 >,
			         < &rcc 0x8 0xff >;     /* in zephyr/dts/arm/st/l4/stm32l471.dtsi:182 */
			resets = < &rctl 0x703 >;       /* in zephyr/dts/arm/st/l4/stm32l471.dtsi:184 */
			interrupts = < 0x32 0x0 >;      /* in zephyr/dts/arm/st/l4/stm32l471.dtsi:185 */
			interrupt-names = "global";     /* in zephyr/dts/arm/st/l4/stm32l471.dtsi:186 */
			st,prescaler = < 0x0 >;         /* in zephyr/dts/arm/st/l4/stm32l471.dtsi:187 */
			status = "disabled";            /* in zephyr/dts/arm/st/l4/stm32l471.dtsi:188 */

			/* node '/soc/timers@40000c00/pwm' defined in zephyr/dts/arm/st/l4/stm32l471.dtsi:190 */
			pwm {
				compatible = "st,stm32-pwm"; /* in zephyr/dts/arm/st/l4/stm32l471.dtsi:191 */
				status = "disabled";         /* in zephyr/dts/arm/st/l4/stm32l471.dtsi:192 */
				#pwm-cells = < 0x3 >;        /* in zephyr/dts/arm/st/l4/stm32l471.dtsi:193 */
			};

			/* node '/soc/timers@40000c00/counter' defined in zephyr/dts/arm/st/l4/stm32l471.dtsi:196 */
			counter {
				compatible = "st,stm32-counter"; /* in zephyr/dts/arm/st/l4/stm32l471.dtsi:197 */
				status = "disabled";             /* in zephyr/dts/arm/st/l4/stm32l471.dtsi:198 */
			};

			/* node '/soc/timers@40000c00/qdec' defined in zephyr/dts/arm/st/l4/stm32l471.dtsi:201 */
			qdec {
				compatible = "st,stm32-qdec";    /* in zephyr/dts/arm/st/l4/stm32l471.dtsi:202 */
				st,input-filter-level = < 0x0 >; /* in zephyr/dts/arm/st/l4/stm32l471.dtsi:203 */
				status = "disabled";             /* in zephyr/dts/arm/st/l4/stm32l471.dtsi:204 */
			};
		};

		/* node '/soc/timers@40001400' defined in zephyr/dts/arm/st/l4/stm32l471.dtsi:208 */
		timers7: timers@40001400 {
			compatible = "st,stm32-timers"; /* in zephyr/dts/arm/st/l4/stm32l471.dtsi:209 */
			reg = < 0x40001400 0x400 >;     /* in zephyr/dts/arm/st/l4/stm32l471.dtsi:210 */
			clocks = < &rcc 0x58 0x20 >,
			         < &rcc 0x8 0xff >;     /* in zephyr/dts/arm/st/l4/stm32l471.dtsi:211 */
			resets = < &rctl 0x705 >;       /* in zephyr/dts/arm/st/l4/stm32l471.dtsi:213 */
			interrupts = < 0x37 0x0 >;      /* in zephyr/dts/arm/st/l4/stm32l471.dtsi:214 */
			interrupt-names = "global";     /* in zephyr/dts/arm/st/l4/stm32l471.dtsi:215 */
			st,prescaler = < 0x0 >;         /* in zephyr/dts/arm/st/l4/stm32l471.dtsi:216 */
			status = "disabled";            /* in zephyr/dts/arm/st/l4/stm32l471.dtsi:217 */

			/* node '/soc/timers@40001400/counter' defined in zephyr/dts/arm/st/l4/stm32l471.dtsi:219 */
			counter {
				compatible = "st,stm32-counter"; /* in zephyr/dts/arm/st/l4/stm32l471.dtsi:220 */
				status = "disabled";             /* in zephyr/dts/arm/st/l4/stm32l471.dtsi:221 */
			};
		};

		/* node '/soc/timers@40013400' defined in zephyr/dts/arm/st/l4/stm32l471.dtsi:225 */
		timers8: timers@40013400 {
			compatible = "st,stm32-timers"; /* in zephyr/dts/arm/st/l4/stm32l471.dtsi:226 */
			reg = < 0x40013400 0x400 >;     /* in zephyr/dts/arm/st/l4/stm32l471.dtsi:227 */
			clocks = < &rcc 0x60 0x2000 >,
			         < &rcc 0x9 0xff >;     /* in zephyr/dts/arm/st/l4/stm32l471.dtsi:228 */
			resets = < &rctl 0x80d >;       /* in zephyr/dts/arm/st/l4/stm32l471.dtsi:230 */
			interrupts = < 0x2b 0x0 >,
			             < 0x2c 0x0 >,
			             < 0x2d 0x0 >,
			             < 0x2e 0x0 >;      /* in zephyr/dts/arm/st/l4/stm32l471.dtsi:231 */
			interrupt-names = "brk",
			                  "up",
			                  "trgcom",
			                  "cc";         /* in zephyr/dts/arm/st/l4/stm32l471.dtsi:232 */
			st,prescaler = < 0x0 >;         /* in zephyr/dts/arm/st/l4/stm32l471.dtsi:233 */
			status = "disabled";            /* in zephyr/dts/arm/st/l4/stm32l471.dtsi:234 */

			/* node '/soc/timers@40013400/pwm' defined in zephyr/dts/arm/st/l4/stm32l471.dtsi:236 */
			pwm {
				compatible = "st,stm32-pwm"; /* in zephyr/dts/arm/st/l4/stm32l471.dtsi:237 */
				status = "disabled";         /* in zephyr/dts/arm/st/l4/stm32l471.dtsi:238 */
				#pwm-cells = < 0x3 >;        /* in zephyr/dts/arm/st/l4/stm32l471.dtsi:239 */
			};

			/* node '/soc/timers@40013400/qdec' defined in zephyr/dts/arm/st/l4/stm32l471.dtsi:242 */
			qdec {
				compatible = "st,stm32-qdec";    /* in zephyr/dts/arm/st/l4/stm32l471.dtsi:243 */
				st,input-filter-level = < 0x0 >; /* in zephyr/dts/arm/st/l4/stm32l471.dtsi:244 */
				status = "disabled";             /* in zephyr/dts/arm/st/l4/stm32l471.dtsi:245 */
			};
		};

		/* node '/soc/timers@40014800' defined in zephyr/dts/arm/st/l4/stm32l471.dtsi:249 */
		timers17: timers@40014800 {
			compatible = "st,stm32-timers"; /* in zephyr/dts/arm/st/l4/stm32l471.dtsi:250 */
			reg = < 0x40014800 0x400 >;     /* in zephyr/dts/arm/st/l4/stm32l471.dtsi:251 */
			clocks = < &rcc 0x60 0x40000 >,
			         < &rcc 0x9 0xff >;     /* in zephyr/dts/arm/st/l4/stm32l471.dtsi:252 */
			resets = < &rctl 0x812 >;       /* in zephyr/dts/arm/st/l4/stm32l471.dtsi:254 */
			interrupts = < 0x1a 0x0 >;      /* in zephyr/dts/arm/st/l4/stm32l471.dtsi:255 */
			interrupt-names = "global";     /* in zephyr/dts/arm/st/l4/stm32l471.dtsi:256 */
			st,prescaler = < 0x0 >;         /* in zephyr/dts/arm/st/l4/stm32l471.dtsi:257 */
			status = "disabled";            /* in zephyr/dts/arm/st/l4/stm32l471.dtsi:258 */

			/* node '/soc/timers@40014800/pwm' defined in zephyr/dts/arm/st/l4/stm32l471.dtsi:260 */
			pwm {
				compatible = "st,stm32-pwm"; /* in zephyr/dts/arm/st/l4/stm32l471.dtsi:261 */
				status = "disabled";         /* in zephyr/dts/arm/st/l4/stm32l471.dtsi:262 */
				#pwm-cells = < 0x3 >;        /* in zephyr/dts/arm/st/l4/stm32l471.dtsi:263 */
			};

			/* node '/soc/timers@40014800/counter' defined in zephyr/dts/arm/st/l4/stm32l471.dtsi:266 */
			counter {
				compatible = "st,stm32-counter"; /* in zephyr/dts/arm/st/l4/stm32l471.dtsi:267 */
				status = "disabled";             /* in zephyr/dts/arm/st/l4/stm32l471.dtsi:268 */
			};
		};

		/* node '/soc/can@40006400' defined in zephyr/dts/arm/st/l4/stm32l471.dtsi:272 */
		can1: can@40006400 {
			compatible = "st,stm32-bxcan";    /* in zephyr/dts/arm/st/l4/stm32l471.dtsi:273 */
			reg = < 0x40006400 0x400 >;       /* in zephyr/dts/arm/st/l4/stm32l471.dtsi:274 */
			interrupts = < 0x13 0x0 >,
			             < 0x14 0x0 >,
			             < 0x15 0x0 >,
			             < 0x16 0x0 >;        /* in zephyr/dts/arm/st/l4/stm32l471.dtsi:275 */
			interrupt-names = "TX",
			                  "RX0",
			                  "RX1",
			                  "SCE";          /* in zephyr/dts/arm/st/l4/stm32l471.dtsi:276 */
			clocks = < &rcc 0x58 0x2000000 >; /* in zephyr/dts/arm/st/l4/stm32l471.dtsi:277 */
			status = "disabled";              /* in zephyr/dts/arm/st/l4/stm32l471.dtsi:278 */
		};

		/* node '/soc/sdmmc@40012800' defined in zephyr/dts/arm/st/l4/stm32l471.dtsi:281 */
		sdmmc1: sdmmc@40012800 {
			compatible = "st,stm32-sdmmc";   /* in zephyr/dts/arm/st/l4/stm32l471.dtsi:282 */
			reg = < 0x40012800 0x400 >;      /* in zephyr/dts/arm/st/l4/stm32l471.dtsi:283 */
			clocks = < &rcc 0x60 0x400 >,
			         < &rcc 0x6 0x33a0088 >; /* in zephyr/dts/arm/st/l4/stm32l471.dtsi:284 */
			resets = < &rctl 0x80a >;        /* in zephyr/dts/arm/st/l4/stm32l471.dtsi:286 */
			interrupts = < 0x31 0x0 >;       /* in zephyr/dts/arm/st/l4/stm32l471.dtsi:287 */
			status = "disabled";             /* in zephyr/dts/arm/st/l4/stm32l471.dtsi:288 */
		};

		/* node '/soc/dac@40007400' defined in zephyr/dts/arm/st/l4/stm32l471.dtsi:291 */
		dac1: dac@40007400 {
			compatible = "st,stm32-dac";       /* in zephyr/dts/arm/st/l4/stm32l471.dtsi:292 */
			reg = < 0x40007400 0x400 >;        /* in zephyr/dts/arm/st/l4/stm32l471.dtsi:293 */
			clocks = < &rcc 0x58 0x20000000 >; /* in zephyr/dts/arm/st/l4/stm32l471.dtsi:294 */
			#io-channel-cells = < 0x1 >;       /* in zephyr/dts/arm/st/l4/stm32l471.dtsi:296 */
			status = "okay";                   /* in zephyr/boards/st/disco_l475_iot1/disco_l475_iot1.dts:313 */
			pinctrl-0 = < &dac1_out1_pa4 >;    /* in zephyr/boards/st/disco_l475_iot1/disco_l475_iot1.dts:314 */
			pinctrl-names = "default";         /* in zephyr/boards/st/disco_l475_iot1/disco_l475_iot1.dts:315 */
		};

		/* node '/soc/adc@50040200' defined in zephyr/dts/arm/st/l4/stm32l471.dtsi:299 */
		adc3: adc@50040200 {
			compatible = "st,stm32-adc";                                /* in zephyr/dts/arm/st/l4/stm32l471.dtsi:300 */
			reg = < 0x50040200 0x100 >;                                 /* in zephyr/dts/arm/st/l4/stm32l471.dtsi:301 */
			clocks = < &rcc 0x4c 0x2000 >;                              /* in zephyr/dts/arm/st/l4/stm32l471.dtsi:302 */
			clock-names = "adcx";                                       /* in zephyr/dts/arm/st/l4/stm32l471.dtsi:303 */
			interrupts = < 0x2f 0x0 >;                                  /* in zephyr/dts/arm/st/l4/stm32l471.dtsi:304 */
			#io-channel-cells = < 0x1 >;                                /* in zephyr/dts/arm/st/l4/stm32l471.dtsi:305 */
			resolutions = < 0x60630c 0x51630c 0x42630c 0x33630c >;      /* in zephyr/dts/arm/st/l4/stm32l471.dtsi:306 */
			sampling-times = < 0x3 0x7 0xd 0x19 0x30 0x5d 0xf8 0x281 >; /* in zephyr/dts/arm/st/l4/stm32l471.dtsi:310 */
			st,adc-sequencer = "programmable";                          /* in zephyr/dts/arm/st/l4/stm32l471.dtsi:311 */
			st,adc-oversampler = "minimal";                             /* in zephyr/dts/arm/st/l4/stm32l471.dtsi:312 */
			st,adc-internal-regulator = "startup-sw-delay";             /* in zephyr/dts/arm/st/l4/stm32l471.dtsi:313 */
			st,adc-has-deep-powerdown;                                  /* in zephyr/dts/arm/st/l4/stm32l471.dtsi:314 */
			st,adc-has-differential-support;                            /* in zephyr/dts/arm/st/l4/stm32l471.dtsi:315 */
			status = "disabled";                                        /* in zephyr/dts/arm/st/l4/stm32l471.dtsi:316 */
		};

		/* node '/soc/otgfs@50000000' defined in zephyr/dts/arm/st/l4/stm32l475.dtsi:13 */
		usbotg_fs: zephyr_udc0: otgfs@50000000 {
			compatible = "st,stm32-otgfs";                                               /* in zephyr/dts/arm/st/l4/stm32l475.dtsi:14 */
			reg = < 0x50000000 0x40000 >;                                                /* in zephyr/dts/arm/st/l4/stm32l475.dtsi:15 */
			interrupts = < 0x43 0x0 >;                                                   /* in zephyr/dts/arm/st/l4/stm32l475.dtsi:16 */
			interrupt-names = "otgfs";                                                   /* in zephyr/dts/arm/st/l4/stm32l475.dtsi:17 */
			num-bidir-endpoints = < 0x6 >;                                               /* in zephyr/dts/arm/st/l4/stm32l475.dtsi:18 */
			ram-size = < 0x500 >;                                                        /* in zephyr/dts/arm/st/l4/stm32l475.dtsi:19 */
			maximum-speed = "full-speed";                                                /* in zephyr/dts/arm/st/l4/stm32l475.dtsi:20 */
			phys = < &otgfs_phy >;                                                       /* in zephyr/dts/arm/st/l4/stm32l475.dtsi:21 */
			clocks = < &rcc 0x4c 0x1000 >,
			         < &rcc 0x6 0x33a0088 >;                                             /* in zephyr/dts/arm/st/l4/stm32l475.dtsi:22 */
			pinctrl-0 = < &usb_otg_fs_dm_pa11 &usb_otg_fs_dp_pa12 &usb_otg_fs_id_pa10 >; /* in zephyr/boards/st/disco_l475_iot1/disco_l475_iot1.dts:285 */
			pinctrl-names = "default";                                                   /* in zephyr/boards/st/disco_l475_iot1/disco_l475_iot1.dts:287 */
			status = "okay";                                                             /* in zephyr/boards/st/disco_l475_iot1/disco_l475_iot1.dts:288 */
		};
	};

	/* node '/cpus' defined in zephyr/dts/arm/st/l4/stm32l4.dtsi:30 */
	cpus {
		#address-cells = < 0x1 >; /* in zephyr/dts/arm/st/l4/stm32l4.dtsi:31 */
		#size-cells = < 0x0 >;    /* in zephyr/dts/arm/st/l4/stm32l4.dtsi:32 */

		/* node '/cpus/cpu@0' defined in zephyr/dts/arm/st/l4/stm32l4.dtsi:34 */
		cpu0: cpu@0 {
			device_type = "cpu";                         /* in zephyr/dts/arm/st/l4/stm32l4.dtsi:35 */
			compatible = "arm,cortex-m4f";               /* in zephyr/dts/arm/st/l4/stm32l4.dtsi:36 */
			reg = < 0x0 >;                               /* in zephyr/dts/arm/st/l4/stm32l4.dtsi:37 */
			cpu-power-states = < &stop0 &stop1 &stop2 >; /* in zephyr/dts/arm/st/l4/stm32l4.dtsi:38 */
		};

		/* node '/cpus/power-states' defined in zephyr/dts/arm/st/l4/stm32l4.dtsi:41 */
		power-states {

			/* node '/cpus/power-states/state0' defined in zephyr/dts/arm/st/l4/stm32l4.dtsi:42 */
			stop0: state0 {
				compatible = "zephyr,power-state";    /* in zephyr/dts/arm/st/l4/stm32l4.dtsi:43 */
				power-state-name = "suspend-to-idle"; /* in zephyr/dts/arm/st/l4/stm32l4.dtsi:44 */
				substate-id = < 0x1 >;                /* in zephyr/dts/arm/st/l4/stm32l4.dtsi:45 */
				min-residency-us = < 0x1f4 >;         /* in zephyr/dts/arm/st/l4/stm32l4.dtsi:46 */
				phandle = < 0x2d >;                   /* in zephyr/dts/arm/st/l4/stm32l4.dtsi:38 */
			};

			/* node '/cpus/power-states/state1' defined in zephyr/dts/arm/st/l4/stm32l4.dtsi:49 */
			stop1: state1 {
				compatible = "zephyr,power-state";    /* in zephyr/dts/arm/st/l4/stm32l4.dtsi:50 */
				power-state-name = "suspend-to-idle"; /* in zephyr/dts/arm/st/l4/stm32l4.dtsi:51 */
				substate-id = < 0x2 >;                /* in zephyr/dts/arm/st/l4/stm32l4.dtsi:52 */
				min-residency-us = < 0x2bc >;         /* in zephyr/dts/arm/st/l4/stm32l4.dtsi:53 */
				phandle = < 0x2e >;                   /* in zephyr/dts/arm/st/l4/stm32l4.dtsi:38 */
			};

			/* node '/cpus/power-states/state2' defined in zephyr/dts/arm/st/l4/stm32l4.dtsi:56 */
			stop2: state2 {
				compatible = "zephyr,power-state";    /* in zephyr/dts/arm/st/l4/stm32l4.dtsi:57 */
				power-state-name = "suspend-to-idle"; /* in zephyr/dts/arm/st/l4/stm32l4.dtsi:58 */
				substate-id = < 0x3 >;                /* in zephyr/dts/arm/st/l4/stm32l4.dtsi:59 */
				min-residency-us = < 0x3e8 >;         /* in zephyr/dts/arm/st/l4/stm32l4.dtsi:60 */
				phandle = < 0x2f >;                   /* in zephyr/dts/arm/st/l4/stm32l4.dtsi:38 */
			};
		};
	};

	/* node '/memory@20000000' defined in zephyr/dts/arm/st/l4/stm32l4.dtsi:65 */
	sram0: memory@20000000 {
		compatible = "zephyr,memory-region",
		             "mmio-sram";            /* in zephyr/dts/arm/st/l4/stm32l4.dtsi:66 */
		zephyr,memory-region = "SRAM0";      /* in zephyr/dts/arm/st/l4/stm32l4.dtsi:67 */
		reg = < 0x20000000 0x18000 >;        /* in zephyr/dts/arm/st/l4/stm32l475Xg.dtsi:10 */
	};

	/* node '/clocks' defined in zephyr/dts/arm/st/l4/stm32l4.dtsi:70 */
	clocks {

		/* node '/clocks/clk-hse' defined in zephyr/dts/arm/st/l4/stm32l4.dtsi:71 */
		clk_hse: clk-hse {
			#clock-cells = < 0x0 >;            /* in zephyr/dts/arm/st/l4/stm32l4.dtsi:72 */
			compatible = "st,stm32-hse-clock"; /* in zephyr/dts/arm/st/l4/stm32l4.dtsi:73 */
			status = "disabled";               /* in zephyr/dts/arm/st/l4/stm32l4.dtsi:74 */
		};

		/* node '/clocks/clk-hsi' defined in zephyr/dts/arm/st/l4/stm32l4.dtsi:77 */
		clk_hsi: clk-hsi {
			#clock-cells = < 0x0 >;         /* in zephyr/dts/arm/st/l4/stm32l4.dtsi:78 */
			compatible = "fixed-clock";     /* in zephyr/dts/arm/st/l4/stm32l4.dtsi:79 */
			clock-frequency = < 0xf42400 >; /* in zephyr/dts/arm/st/l4/stm32l4.dtsi:80 */
			status = "okay";                /* in zephyr/boards/st/disco_l475_iot1/disco_l475_iot1.dts:96 */
			phandle = < 0x30 >;             /* in zephyr/boards/st/disco_l475_iot1/disco_l475_iot1.dts:111 */
		};

		/* node '/clocks/clk-msi' defined in zephyr/dts/arm/st/l4/stm32l4.dtsi:84 */
		clk_msi: clk-msi {
			#clock-cells = < 0x0 >;            /* in zephyr/dts/arm/st/l4/stm32l4.dtsi:85 */
			compatible = "st,stm32-msi-clock"; /* in zephyr/dts/arm/st/l4/stm32l4.dtsi:86 */
			status = "okay";                   /* in zephyr/boards/st/disco_l475_iot1/disco_l475_iot1.dts:100 */
			msi-pll-mode;                      /* in zephyr/boards/st/disco_l475_iot1/disco_l475_iot1.dts:101 */
			msi-range = < 0xb >;               /* in zephyr/boards/st/disco_l475_iot1/disco_l475_iot1.dts:102 */
		};

		/* node '/clocks/clk-lse' defined in zephyr/dts/arm/st/l4/stm32l4.dtsi:91 */
		clk_lse: clk-lse {
			#clock-cells = < 0x0 >;            /* in zephyr/dts/arm/st/l4/stm32l4.dtsi:92 */
			compatible = "st,stm32-lse-clock"; /* in zephyr/dts/arm/st/l4/stm32l4.dtsi:93 */
			clock-frequency = < 0x8000 >;      /* in zephyr/dts/arm/st/l4/stm32l4.dtsi:94 */
			driving-capability = < 0x0 >;      /* in zephyr/dts/arm/st/l4/stm32l4.dtsi:95 */
			status = "okay";                   /* in zephyr/boards/st/disco_l475_iot1/disco_l475_iot1.dts:92 */
		};

		/* node '/clocks/clk-lsi' defined in zephyr/dts/arm/st/l4/stm32l4.dtsi:99 */
		clk_lsi: clk-lsi {
			#clock-cells = < 0x0 >;       /* in zephyr/dts/arm/st/l4/stm32l4.dtsi:100 */
			compatible = "fixed-clock";   /* in zephyr/dts/arm/st/l4/stm32l4.dtsi:101 */
			clock-frequency = < 0x7d00 >; /* in zephyr/dts/arm/st/l4/stm32l4.dtsi:102 */
			status = "okay";              /* in zephyr/boards/st/disco_l475_iot1/disco_l475_iot1.dts:88 */
		};

		/* node '/clocks/pll' defined in zephyr/dts/arm/st/l4/stm32l4.dtsi:106 */
		pll: pll {
			#clock-cells = < 0x0 >;              /* in zephyr/dts/arm/st/l4/stm32l4.dtsi:107 */
			compatible = "st,stm32l4-pll-clock"; /* in zephyr/dts/arm/st/l4/stm32l4.dtsi:108 */
			div-m = < 0x1 >;                     /* in zephyr/boards/st/disco_l475_iot1/disco_l475_iot1.dts:106 */
			mul-n = < 0x14 >;                    /* in zephyr/boards/st/disco_l475_iot1/disco_l475_iot1.dts:107 */
			div-p = < 0x7 >;                     /* in zephyr/boards/st/disco_l475_iot1/disco_l475_iot1.dts:108 */
			div-q = < 0x2 >;                     /* in zephyr/boards/st/disco_l475_iot1/disco_l475_iot1.dts:109 */
			div-r = < 0x4 >;                     /* in zephyr/boards/st/disco_l475_iot1/disco_l475_iot1.dts:110 */
			clocks = < &clk_hsi >;               /* in zephyr/boards/st/disco_l475_iot1/disco_l475_iot1.dts:111 */
			status = "okay";                     /* in zephyr/boards/st/disco_l475_iot1/disco_l475_iot1.dts:112 */
			phandle = < 0x3 >;                   /* in zephyr/boards/st/disco_l475_iot1/disco_l475_iot1.dts:116 */
		};

		/* node '/clocks/pllsai1' defined in zephyr/dts/arm/st/l4/stm32l4.dtsi:112 */
		pllsai1: pllsai1 {
			#clock-cells = < 0x0 >;                 /* in zephyr/dts/arm/st/l4/stm32l4.dtsi:113 */
			compatible = "st,stm32l4-pllsai-clock"; /* in zephyr/dts/arm/st/l4/stm32l4.dtsi:114 */
			status = "disabled";                    /* in zephyr/dts/arm/st/l4/stm32l4.dtsi:115 */
		};

		/* node '/clocks/pllsai2' defined in zephyr/dts/arm/st/l4/stm32l471.dtsi:18 */
		pllsai2: pllsai2 {
			#clock-cells = < 0x0 >;                 /* in zephyr/dts/arm/st/l4/stm32l471.dtsi:19 */
			compatible = "st,stm32l4-pllsai-clock"; /* in zephyr/dts/arm/st/l4/stm32l471.dtsi:20 */
			status = "disabled";                    /* in zephyr/dts/arm/st/l4/stm32l471.dtsi:21 */
		};
	};

	/* node '/mcos' defined in zephyr/dts/arm/st/l4/stm32l4.dtsi:119 */
	mcos {

		/* node '/mcos/mco1' defined in zephyr/dts/arm/st/l4/stm32l4.dtsi:120 */
		mco1: mco1 {
			compatible = "st,stm32-clock-mco"; /* in zephyr/dts/arm/st/l4/stm32l4.dtsi:121 */
			status = "disabled";               /* in zephyr/dts/arm/st/l4/stm32l4.dtsi:122 */
		};
	};

	/* node '/dietemp' defined in zephyr/dts/arm/st/l4/stm32l4.dtsi:552 */
	die_temp: dietemp {
		compatible = "st,stm32-temp-cal"; /* in zephyr/dts/arm/st/l4/stm32l4.dtsi:553 */
		ts-cal1-addr = < 0x1fff75a8 >;    /* in zephyr/dts/arm/st/l4/stm32l4.dtsi:554 */
		ts-cal2-addr = < 0x1fff75ca >;    /* in zephyr/dts/arm/st/l4/stm32l4.dtsi:555 */
		ts-cal1-temp = < 0x1e >;          /* in zephyr/dts/arm/st/l4/stm32l4.dtsi:556 */
		ts-cal-vrefanalog = < 0xbb8 >;    /* in zephyr/dts/arm/st/l4/stm32l4.dtsi:558 */
		io-channels = < &adc1 0x11 >;     /* in zephyr/dts/arm/st/l4/stm32l4.dtsi:559 */
		ts-cal2-temp = < 0x6e >;          /* in zephyr/dts/arm/st/l4/stm32l471.dtsi:329 */
		status = "okay";                  /* in zephyr/boards/st/disco_l475_iot1/disco_l475_iot1.dts:309 */
	};

	/* node '/vref' defined in zephyr/dts/arm/st/l4/stm32l4.dtsi:563 */
	vref: vref {
		compatible = "st,stm32-vref";      /* in zephyr/dts/arm/st/l4/stm32l4.dtsi:564 */
		vrefint-cal-addr = < 0x1fff75aa >; /* in zephyr/dts/arm/st/l4/stm32l4.dtsi:565 */
		vrefint-cal-mv = < 0xbb8 >;        /* in zephyr/dts/arm/st/l4/stm32l4.dtsi:566 */
		io-channels = < &adc1 0x0 >;       /* in zephyr/dts/arm/st/l4/stm32l4.dtsi:567 */
		status = "okay";                   /* in zephyr/boards/st/disco_l475_iot1/disco_l475_iot1.dts:358 */
	};

	/* node '/vbat' defined in zephyr/dts/arm/st/l4/stm32l4.dtsi:571 */
	vbat: vbat {
		compatible = "st,stm32-vbat"; /* in zephyr/dts/arm/st/l4/stm32l4.dtsi:572 */
		ratio = < 0x3 >;              /* in zephyr/dts/arm/st/l4/stm32l4.dtsi:573 */
		io-channels = < &adc1 0x12 >; /* in zephyr/dts/arm/st/l4/stm32l4.dtsi:574 */
		status = "okay";              /* in zephyr/boards/st/disco_l475_iot1/disco_l475_iot1.dts:362 */
	};

	/* node '/smbus1' defined in zephyr/dts/arm/st/l4/stm32l4.dtsi:578 */
	smbus1: smbus1 {
		compatible = "st,stm32-smbus"; /* in zephyr/dts/arm/st/l4/stm32l4.dtsi:579 */
		#address-cells = < 0x1 >;      /* in zephyr/dts/arm/st/l4/stm32l4.dtsi:580 */
		#size-cells = < 0x0 >;         /* in zephyr/dts/arm/st/l4/stm32l4.dtsi:581 */
		i2c = < &i2c1 >;               /* in zephyr/dts/arm/st/l4/stm32l4.dtsi:582 */
		status = "disabled";           /* in zephyr/dts/arm/st/l4/stm32l4.dtsi:583 */
	};

	/* node '/smbus3' defined in zephyr/dts/arm/st/l4/stm32l4.dtsi:586 */
	smbus3: smbus3 {
		compatible = "st,stm32-smbus"; /* in zephyr/dts/arm/st/l4/stm32l4.dtsi:587 */
		#address-cells = < 0x1 >;      /* in zephyr/dts/arm/st/l4/stm32l4.dtsi:588 */
		#size-cells = < 0x0 >;         /* in zephyr/dts/arm/st/l4/stm32l4.dtsi:589 */
		i2c = < &i2c3 >;               /* in zephyr/dts/arm/st/l4/stm32l4.dtsi:590 */
		status = "disabled";           /* in zephyr/dts/arm/st/l4/stm32l4.dtsi:591 */
	};

	/* node '/memory@10000000' defined in zephyr/dts/arm/st/l4/stm32l471.dtsi:12 */
	sram1: memory@10000000 {
		compatible = "zephyr,memory-region",
		             "mmio-sram";            /* in zephyr/dts/arm/st/l4/stm32l471.dtsi:13 */
		zephyr,memory-region = "SRAM1";      /* in zephyr/dts/arm/st/l4/stm32l471.dtsi:14 */
		reg = < 0x10000000 0x8000 >;         /* in zephyr/dts/arm/st/l4/stm32l475Xg.dtsi:14 */
	};

	/* node '/smbus2' defined in zephyr/dts/arm/st/l4/stm32l471.dtsi:332 */
	smbus2: smbus2 {
		compatible = "st,stm32-smbus"; /* in zephyr/dts/arm/st/l4/stm32l471.dtsi:333 */
		#address-cells = < 0x1 >;      /* in zephyr/dts/arm/st/l4/stm32l471.dtsi:334 */
		#size-cells = < 0x0 >;         /* in zephyr/dts/arm/st/l4/stm32l471.dtsi:335 */
		i2c = < &i2c2 >;               /* in zephyr/dts/arm/st/l4/stm32l471.dtsi:336 */
		status = "disabled";           /* in zephyr/dts/arm/st/l4/stm32l471.dtsi:337 */
	};

	/* node '/otgfs_phy' defined in zephyr/dts/arm/st/l4/stm32l475.dtsi:28 */
	otgfs_phy: otgfs_phy {
		compatible = "usb-nop-xceiv"; /* in zephyr/dts/arm/st/l4/stm32l475.dtsi:29 */
		#phy-cells = < 0x0 >;         /* in zephyr/dts/arm/st/l4/stm32l475.dtsi:30 */
		phandle = < 0x29 >;           /* in zephyr/dts/arm/st/l4/stm32l475.dtsi:21 */
	};

	/* node '/connector' defined in zephyr/boards/st/disco_l475_iot1/arduino_r3_connector.dtsi:10 */
	arduino_header: connector {
		compatible = "arduino-header-r3";          /* in zephyr/boards/st/disco_l475_iot1/arduino_r3_connector.dtsi:11 */
		#gpio-cells = < 0x2 >;                     /* in zephyr/boards/st/disco_l475_iot1/arduino_r3_connector.dtsi:12 */
		gpio-map-mask = < 0xffffffff 0xffffffc0 >; /* in zephyr/boards/st/disco_l475_iot1/arduino_r3_connector.dtsi:13 */
		gpio-map-pass-thru = < 0x0 0x3f >;         /* in zephyr/boards/st/disco_l475_iot1/arduino_r3_connector.dtsi:14 */
		gpio-map = < 0x0 0x0 &gpioc 0x5 0x0 >,
		           < 0x1 0x0 &gpioc 0x4 0x0 >,
		           < 0x2 0x0 &gpioc 0x3 0x0 >,
		           < 0x3 0x0 &gpioc 0x2 0x0 >,
		           < 0x4 0x0 &gpioc 0x1 0x0 >,
		           < 0x5 0x0 &gpioc 0x0 0x0 >,
		           < 0x6 0x0 &gpioa 0x1 0x0 >,
		           < 0x7 0x0 &gpioa 0x0 0x0 >,
		           < 0x8 0x0 &gpiod 0xe 0x0 >,
		           < 0x9 0x0 &gpiob 0x0 0x0 >,
		           < 0xa 0x0 &gpioa 0x3 0x0 >,
		           < 0xb 0x0 &gpiob 0x4 0x0 >,
		           < 0xc 0x0 &gpiob 0x1 0x0 >,
		           < 0xd 0x0 &gpioa 0x4 0x0 >,
		           < 0xe 0x0 &gpiob 0x2 0x0 >,
		           < 0xf 0x0 &gpioa 0xf 0x0 >,
		           < 0x10 0x0 &gpioa 0x2 0x0 >,
		           < 0x11 0x0 &gpioa 0x7 0x0 >,
		           < 0x12 0x0 &gpioa 0x6 0x0 >,
		           < 0x13 0x0 &gpioa 0x5 0x0 >,
		           < 0x14 0x0 &gpiob 0x9 0x0 >,
		           < 0x15 0x0 &gpiob 0x8 0x0 >;    /* in zephyr/boards/st/disco_l475_iot1/arduino_r3_connector.dtsi:15 */
	};

	/* node '/leds' defined in zephyr/boards/st/disco_l475_iot1/disco_l475_iot1.dts:28 */
	leds {
		compatible = "gpio-leds"; /* in zephyr/boards/st/disco_l475_iot1/disco_l475_iot1.dts:29 */

		/* node '/leds/led_1' defined in zephyr/boards/st/disco_l475_iot1/disco_l475_iot1.dts:31 */
		green_led_1: led_1 {
			gpios = < &gpioa 0x5 0x0 >; /* in zephyr/boards/st/disco_l475_iot1/disco_l475_iot1.dts:32 */
			label = "User LD1";         /* in zephyr/boards/st/disco_l475_iot1/disco_l475_iot1.dts:33 */
		};

		/* node '/leds/led_2' defined in zephyr/boards/st/disco_l475_iot1/disco_l475_iot1.dts:36 */
		green_led_2: led_2 {
			gpios = < &gpiob 0xe 0x0 >; /* in zephyr/boards/st/disco_l475_iot1/disco_l475_iot1.dts:37 */
			label = "User LD2";         /* in zephyr/boards/st/disco_l475_iot1/disco_l475_iot1.dts:38 */
		};
	};

	/* node '/gpio_keys' defined in zephyr/boards/st/disco_l475_iot1/disco_l475_iot1.dts:42 */
	gpio_keys {
		compatible = "gpio-keys"; /* in zephyr/boards/st/disco_l475_iot1/disco_l475_iot1.dts:43 */

		/* node '/gpio_keys/button_0' defined in zephyr/boards/st/disco_l475_iot1/disco_l475_iot1.dts:45 */
		user_button: button_0 {
			label = "User";             /* in zephyr/boards/st/disco_l475_iot1/disco_l475_iot1.dts:46 */
			gpios = < &gpioc 0xd 0x1 >; /* in zephyr/boards/st/disco_l475_iot1/disco_l475_iot1.dts:47 */
			zephyr,code = < 0xb >;      /* in zephyr/boards/st/disco_l475_iot1/disco_l475_iot1.dts:48 */
		};
	};

	/* node '/pwmleds' defined in zephyr/boards/st/disco_l475_iot1/disco_l475_iot1.dts:52 */
	pwmleds: pwmleds {
		compatible = "pwm-leds"; /* in zephyr/boards/st/disco_l475_iot1/disco_l475_iot1.dts:53 */
		status = "disabled";     /* in zephyr/boards/st/disco_l475_iot1/disco_l475_iot1.dts:55 */

		/* node '/pwmleds/green_led_1' defined in zephyr/boards/st/disco_l475_iot1/disco_l475_iot1.dts:61 */
		green_pwm_1: green_led_1 {
			pwms = < &pwm2 0x1 0x1312d00 0x0 >; /* in zephyr/boards/st/disco_l475_iot1/disco_l475_iot1.dts:62 */
			label = "green LD1";                /* in zephyr/boards/st/disco_l475_iot1/disco_l475_iot1.dts:63 */
		};

		/* node '/pwmleds/green_led_2' defined in zephyr/boards/st/disco_l475_iot1/disco_l475_iot1.dts:66 */
		green_pwm_2: green_led_2 {
			pwms = < &pwm15 0x1 0x1312d00 0x0 >; /* in zephyr/boards/st/disco_l475_iot1/disco_l475_iot1.dts:67 */
			label = "green LD2";                 /* in zephyr/boards/st/disco_l475_iot1/disco_l475_iot1.dts:68 */
		};
	};
};
